AUTOSAR XML (schema 4-0-3)
standard types defined: uint8, Boolean, UInt16, UInt32, UInt8
package /AUTOSAR_Platform/DataConstrs
  range DC_Boolean: raw 0..1
  range DC_UInt16: raw 0..65535
  range DC_UInt8: raw 0..255
package /PATAC/Facility/DataTypes/Implementation
  compu method COMPU_Boolean: 0=FALSE, 1=TRUE
  unit NoUnit: factor-si-to-unit=1, offset-si-to-unit=0
package /PATAC/MSM/ComponentTypes
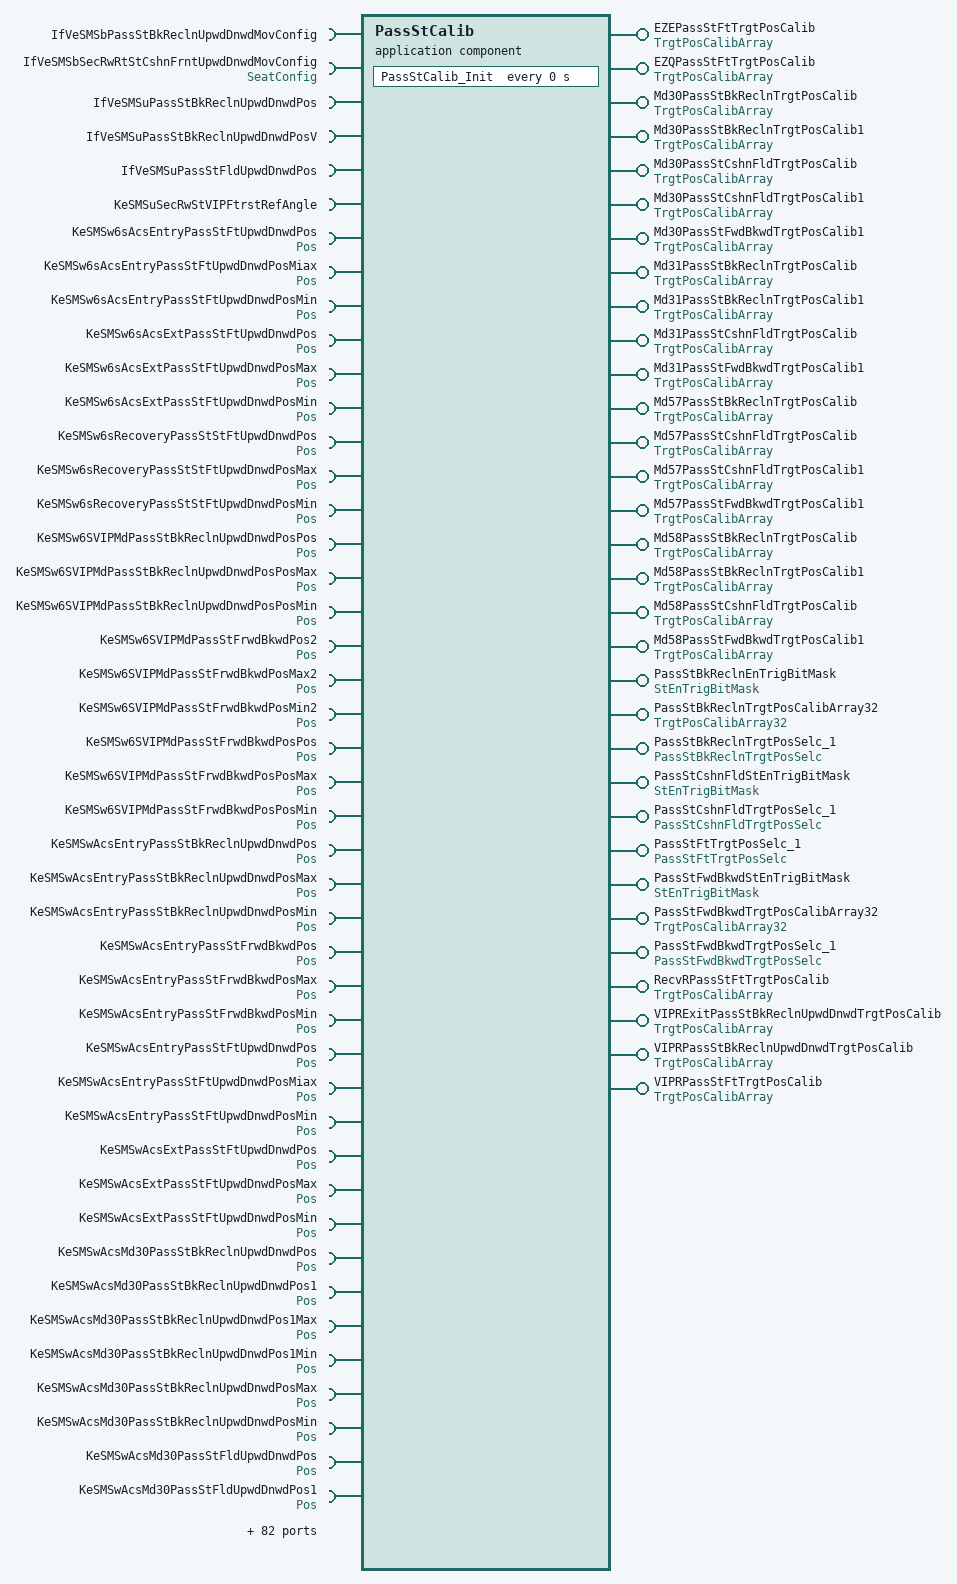
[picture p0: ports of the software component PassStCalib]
  application sw component type PassStCalib
    32 x provide port:
      EZEPassStFtTrgtPosCalib: nonqueued-sender-com-spec{data-element=TrgtPosArray, init-value=[4095, 4095, 4095]}, provided-interface=TrgtPosCalibArray
      EZQPassStFtTrgtPosCalib: nonqueued-sender-com-spec{data-element=TrgtPosArray, init-value=[4095, 4095, 4095]}, provided-interface=TrgtPosCalibArray
      Md30PassStBkReclnTrgtPosCalib: nonqueued-sender-com-spec{data-element=TrgtPosArray, init-value=[4095, 4095, 4095]}, provided-interface=TrgtPosCalibArray
      Md30PassStBkReclnTrgtPosCalib1: nonqueued-sender-com-spec{data-element=TrgtPosArray, init-value=[4095, 4095, 4095]}, provided-interface=TrgtPosCalibArray
      Md30PassStCshnFldTrgtPosCalib: nonqueued-sender-com-spec{data-element=TrgtPosArray, init-value=[4095, 4095, 4095]}, provided-interface=TrgtPosCalibArray
      Md30PassStCshnFldTrgtPosCalib1: nonqueued-sender-com-spec{data-element=TrgtPosArray, init-value=[4095, 4095, 4095]}, provided-interface=TrgtPosCalibArray
      Md30PassStFwdBkwdTrgtPosCalib1: nonqueued-sender-com-spec{data-element=TrgtPosArray, init-value=[4095, 4095, 4095]}, provided-interface=TrgtPosCalibArray
      Md31PassStBkReclnTrgtPosCalib: nonqueued-sender-com-spec{data-element=TrgtPosArray, init-value=[4095, 4095, 4095]}, provided-interface=TrgtPosCalibArray
      Md31PassStBkReclnTrgtPosCalib1: nonqueued-sender-com-spec{data-element=TrgtPosArray, init-value=[4095, 4095, 4095]}, provided-interface=TrgtPosCalibArray
      Md31PassStCshnFldTrgtPosCalib: nonqueued-sender-com-spec{data-element=TrgtPosArray, init-value=[4095, 4095, 4095]}, provided-interface=TrgtPosCalibArray
      Md31PassStFwdBkwdTrgtPosCalib1: nonqueued-sender-com-spec{data-element=TrgtPosArray, init-value=[4095, 4095, 4095]}, provided-interface=TrgtPosCalibArray
      Md57PassStBkReclnTrgtPosCalib: nonqueued-sender-com-spec{data-element=TrgtPosArray, init-value=[0, 0, 0]}, provided-interface=TrgtPosCalibArray
      Md57PassStCshnFldTrgtPosCalib: nonqueued-sender-com-spec{data-element=TrgtPosArray, init-value=[0, 0, 0]}, provided-interface=TrgtPosCalibArray
      Md57PassStCshnFldTrgtPosCalib1: nonqueued-sender-com-spec{data-element=TrgtPosArray, init-value=[0, 0, 0]}, provided-interface=TrgtPosCalibArray
      Md57PassStFwdBkwdTrgtPosCalib1: nonqueued-sender-com-spec{data-element=TrgtPosArray, init-value=[0, 0, 0]}, provided-interface=TrgtPosCalibArray
      Md58PassStBkReclnTrgtPosCalib: nonqueued-sender-com-spec{data-element=TrgtPosArray, init-value=[4095, 4095, 4095]}, provided-interface=TrgtPosCalibArray
      Md58PassStBkReclnTrgtPosCalib1: nonqueued-sender-com-spec{data-element=TrgtPosArray, init-value=[0, 0, 0]}, provided-interface=TrgtPosCalibArray
      Md58PassStCshnFldTrgtPosCalib: nonqueued-sender-com-spec{data-element=TrgtPosArray, init-value=[0, 0, 0]}, provided-interface=TrgtPosCalibArray
      Md58PassStFwdBkwdTrgtPosCalib1: nonqueued-sender-com-spec{data-element=TrgtPosArray, init-value=[0, 0, 0]}, provided-interface=TrgtPosCalibArray
      PassStBkReclnEnTrigBitMask: nonqueued-sender-com-spec{data-element=StEnTrigBitMask/Val, init-value=0}, provided-interface=StEnTrigBitMask
      PassStBkReclnTrgtPosCalibArray32: nonqueued-sender-com-spec{data-element=TrgtPosArray32, init-value=96 x 0}, provided-interface=TrgtPosCalibArray32
      PassStBkReclnTrgtPosSelc_1: server-com-spec{operation=PassStBkReclnTrgtPosSelc/Cal, queue-length=1}, provided-interface=PassStBkReclnTrgtPosSelc
      PassStCshnFldStEnTrigBitMask: nonqueued-sender-com-spec{data-element=StEnTrigBitMask/Val, init-value=0}, provided-interface=StEnTrigBitMask
      PassStCshnFldTrgtPosSelc_1: server-com-spec{operation=PassStCshnFldTrgtPosSelc/Cal, queue-length=1}, provided-interface=PassStCshnFldTrgtPosSelc
      PassStFtTrgtPosSelc_1: server-com-spec{operation=PassStFtTrgtPosSelc/Cal, queue-length=1}, provided-interface=PassStFtTrgtPosSelc
      PassStFwdBkwdStEnTrigBitMask: nonqueued-sender-com-spec{data-element=StEnTrigBitMask/Val, init-value=0}, provided-interface=StEnTrigBitMask
      PassStFwdBkwdTrgtPosCalibArray32: nonqueued-sender-com-spec{data-element=TrgtPosArray32, init-value=96 x 0}, provided-interface=TrgtPosCalibArray32
      PassStFwdBkwdTrgtPosSelc_1: server-com-spec{operation=PassStFwdBkwdTrgtPosSelc/Cal, queue-length=1}, provided-interface=PassStFwdBkwdTrgtPosSelc
      RecvRPassStFtTrgtPosCalib: nonqueued-sender-com-spec{data-element=TrgtPosArray, init-value=[4095, 4095, 4095]}, provided-interface=TrgtPosCalibArray
      VIPRExitPassStBkReclnUpwdDnwdTrgtPosCalib: nonqueued-sender-com-spec{data-element=TrgtPosArray, init-value=[4095, 4095, 4095]}, provided-interface=TrgtPosCalibArray
      VIPRPassStBkReclnUpwdDnwdTrgtPosCalib: nonqueued-sender-com-spec{data-element=TrgtPosArray, init-value=[4095, 4095, 4095]}, provided-interface=TrgtPosCalibArray
      VIPRPassStFtTrgtPosCalib: nonqueued-sender-com-spec{data-element=TrgtPosArray, init-value=[4095, 4095, 4095]}, provided-interface=TrgtPosCalibArray
    126 x require port:
      IfVeSMSbPassStBkReclnUpwdDnwdMovConfig: nonqueued-receiver-com-spec{data-element=IfVeSMSbPassStBkReclnUpwdDnwdMovConfig/Val, filter=data-filter-type=ALWAYS, init-value=0}, required-interface=IfVeSMSbPassStBkReclnUpwdDnwdMovConfig
      IfVeSMSbSecRwRtStCshnFrntUpwdDnwdMovConfig: nonqueued-receiver-com-spec{data-element=SeatConfig/Val, filter=data-filter-type=ALWAYS, init-value=0}, required-interface=SeatConfig
      IfVeSMSuPassStBkReclnUpwdDnwdPos: nonqueued-receiver-com-spec{data-element=IfVeSMSuPassStBkReclnUpwdDnwdPos/Val, filter=data-filter-type=ALWAYS, init-value=0}, required-interface=IfVeSMSuPassStBkReclnUpwdDnwdPos
      IfVeSMSuPassStBkReclnUpwdDnwdPosV: nonqueued-receiver-com-spec{data-element=IfVeSMSuPassStBkReclnUpwdDnwdPosV/Val, filter=data-filter-type=ALWAYS, init-value=0}, required-interface=IfVeSMSuPassStBkReclnUpwdDnwdPosV
      IfVeSMSuPassStFldUpwdDnwdPos: nonqueued-receiver-com-spec{data-element=IfVeSMSuPassStFldUpwdDnwdPos/Val, filter=data-filter-type=ALWAYS, init-value=0}, required-interface=IfVeSMSuPassStFldUpwdDnwdPos
      KeSMSuSecRwStVIPFtrstRefAngle: parameter-require-com-spec{init-value=110, parameter=KeSMSuSecRwStVIPFtrstRefAngle/Val}, required-interface=KeSMSuSecRwStVIPFtrstRefAngle
      KeSMSw6sAcsEntryPassStFtUpwdDnwdPos: parameter-require-com-spec{init-value=0, parameter=Pos/Val}, required-interface=Pos
      KeSMSw6sAcsEntryPassStFtUpwdDnwdPosMiax: parameter-require-com-spec{init-value=0, parameter=Pos/Val}, required-interface=Pos
      KeSMSw6sAcsEntryPassStFtUpwdDnwdPosMin: parameter-require-com-spec{init-value=0, parameter=Pos/Val}, required-interface=Pos
      KeSMSw6sAcsExtPassStFtUpwdDnwdPos: parameter-require-com-spec{init-value=0, parameter=Pos/Val}, required-interface=Pos
      KeSMSw6sAcsExtPassStFtUpwdDnwdPosMax: parameter-require-com-spec{init-value=0, parameter=Pos/Val}, required-interface=Pos
      KeSMSw6sAcsExtPassStFtUpwdDnwdPosMin: parameter-require-com-spec{init-value=0, parameter=Pos/Val}, required-interface=Pos
      KeSMSw6sRecoveryPassStStFtUpwdDnwdPos: parameter-require-com-spec{init-value=0, parameter=Pos/Val}, required-interface=Pos
      KeSMSw6sRecoveryPassStStFtUpwdDnwdPosMax: parameter-require-com-spec{init-value=0, parameter=Pos/Val}, required-interface=Pos
      KeSMSw6sRecoveryPassStStFtUpwdDnwdPosMin: parameter-require-com-spec{init-value=0, parameter=Pos/Val}, required-interface=Pos
      KeSMSw6SVIPMdPassStBkReclnUpwdDnwdPosPos: parameter-require-com-spec{init-value=0, parameter=Pos/Val}, required-interface=Pos
      KeSMSw6SVIPMdPassStBkReclnUpwdDnwdPosPosMax: parameter-require-com-spec{init-value=0, parameter=Pos/Val}, required-interface=Pos
      KeSMSw6SVIPMdPassStBkReclnUpwdDnwdPosPosMin: parameter-require-com-spec{init-value=0, parameter=Pos/Val}, required-interface=Pos
      KeSMSw6SVIPMdPassStFrwdBkwdPos2: parameter-require-com-spec{init-value=0, parameter=Pos/Val}, required-interface=Pos
      KeSMSw6SVIPMdPassStFrwdBkwdPosMax2: parameter-require-com-spec{init-value=0, parameter=Pos/Val}, required-interface=Pos
      KeSMSw6SVIPMdPassStFrwdBkwdPosMin2: parameter-require-com-spec{init-value=0, parameter=Pos/Val}, required-interface=Pos
      KeSMSw6SVIPMdPassStFrwdBkwdPosPos: parameter-require-com-spec{init-value=0, parameter=Pos/Val}, required-interface=Pos
      KeSMSw6SVIPMdPassStFrwdBkwdPosPosMax: parameter-require-com-spec{init-value=0, parameter=Pos/Val}, required-interface=Pos
      KeSMSw6SVIPMdPassStFrwdBkwdPosPosMin: parameter-require-com-spec{init-value=0, parameter=Pos/Val}, required-interface=Pos
      KeSMSwAcsEntryPassStBkReclnUpwdDnwdPos: parameter-require-com-spec{init-value=0, parameter=Pos/Val}, required-interface=Pos
      KeSMSwAcsEntryPassStBkReclnUpwdDnwdPosMax: parameter-require-com-spec{init-value=0, parameter=Pos/Val}, required-interface=Pos
      KeSMSwAcsEntryPassStBkReclnUpwdDnwdPosMin: parameter-require-com-spec{init-value=0, parameter=Pos/Val}, required-interface=Pos
      KeSMSwAcsEntryPassStFrwdBkwdPos: parameter-require-com-spec{init-value=0, parameter=Pos/Val}, required-interface=Pos
      KeSMSwAcsEntryPassStFrwdBkwdPosMax: parameter-require-com-spec{init-value=0, parameter=Pos/Val}, required-interface=Pos
      KeSMSwAcsEntryPassStFrwdBkwdPosMin: parameter-require-com-spec{init-value=0, parameter=Pos/Val}, required-interface=Pos
      KeSMSwAcsEntryPassStFtUpwdDnwdPos: parameter-require-com-spec{init-value=0, parameter=Pos/Val}, required-interface=Pos
      KeSMSwAcsEntryPassStFtUpwdDnwdPosMiax: parameter-require-com-spec{init-value=0, parameter=Pos/Val}, required-interface=Pos
      KeSMSwAcsEntryPassStFtUpwdDnwdPosMin: parameter-require-com-spec{init-value=0, parameter=Pos/Val}, required-interface=Pos
      KeSMSwAcsExtPassStFtUpwdDnwdPos: parameter-require-com-spec{init-value=0, parameter=Pos/Val}, required-interface=Pos
      KeSMSwAcsExtPassStFtUpwdDnwdPosMax: parameter-require-com-spec{init-value=0, parameter=Pos/Val}, required-interface=Pos
      KeSMSwAcsExtPassStFtUpwdDnwdPosMin: parameter-require-com-spec{init-value=0, parameter=Pos/Val}, required-interface=Pos
      KeSMSwAcsMd30PassStBkReclnUpwdDnwdPos: parameter-require-com-spec{init-value=0, parameter=Pos/Val}, required-interface=Pos
      KeSMSwAcsMd30PassStBkReclnUpwdDnwdPos1: parameter-require-com-spec{init-value=0, parameter=Pos/Val}, required-interface=Pos
      KeSMSwAcsMd30PassStBkReclnUpwdDnwdPos1Max: parameter-require-com-spec{init-value=0, parameter=Pos/Val}, required-interface=Pos
      KeSMSwAcsMd30PassStBkReclnUpwdDnwdPos1Min: parameter-require-com-spec{init-value=0, parameter=Pos/Val}, required-interface=Pos
      KeSMSwAcsMd30PassStBkReclnUpwdDnwdPosMax: parameter-require-com-spec{init-value=0, parameter=Pos/Val}, required-interface=Pos
      KeSMSwAcsMd30PassStBkReclnUpwdDnwdPosMin: parameter-require-com-spec{init-value=0, parameter=Pos/Val}, required-interface=Pos
      KeSMSwAcsMd30PassStFldUpwdDnwdPos: parameter-require-com-spec{init-value=0, parameter=Pos/Val}, required-interface=Pos
      KeSMSwAcsMd30PassStFldUpwdDnwdPos1: parameter-require-com-spec{init-value=0, parameter=Pos/Val}, required-interface=Pos
      KeSMSwAcsMd30PassStFldUpwdDnwdPos1Max: parameter-require-com-spec{init-value=0, parameter=Pos/Val}, required-interface=Pos
      KeSMSwAcsMd30PassStFldUpwdDnwdPos1Min: parameter-require-com-spec{init-value=0, parameter=Pos/Val}, required-interface=Pos
      KeSMSwAcsMd30PassStFldUpwdDnwdPosMax: parameter-require-com-spec{init-value=0, parameter=Pos/Val}, required-interface=Pos
      KeSMSwAcsMd30PassStFldUpwdDnwdPosMin: parameter-require-com-spec{init-value=0, parameter=Pos/Val}, required-interface=Pos
      KeSMSwAcsMd30PassStFrwdBkwdPos: parameter-require-com-spec{init-value=0, parameter=Pos/Val}, required-interface=Pos
      KeSMSwAcsMd30PassStFrwdBkwdPos1: parameter-require-com-spec{init-value=0, parameter=Pos/Val}, required-interface=Pos
      KeSMSwAcsMd30PassStFrwdBkwdPos1Max: parameter-require-com-spec{init-value=0, parameter=Pos/Val}, required-interface=Pos
      KeSMSwAcsMd30PassStFrwdBkwdPos1Min: parameter-require-com-spec{init-value=0, parameter=Pos/Val}, required-interface=Pos
      KeSMSwAcsMd30PassStFrwdBkwdPosMax: parameter-require-com-spec{init-value=0, parameter=Pos/Val}, required-interface=Pos
      KeSMSwAcsMd30PassStFrwdBkwdPosMin: parameter-require-com-spec{init-value=0, parameter=Pos/Val}, required-interface=Pos
      KeSMSwAcsMd31PassStBkReclnUpwdDnwdPos: parameter-require-com-spec{init-value=0, parameter=Pos/Val}, required-interface=Pos
      KeSMSwAcsMd31PassStBkReclnUpwdDnwdPos1: parameter-require-com-spec{init-value=0, parameter=Pos/Val}, required-interface=Pos
      KeSMSwAcsMd31PassStBkReclnUpwdDnwdPos1Max: parameter-require-com-spec{init-value=0, parameter=Pos/Val}, required-interface=Pos
      KeSMSwAcsMd31PassStBkReclnUpwdDnwdPos1Min: parameter-require-com-spec{init-value=0, parameter=Pos/Val}, required-interface=Pos
      KeSMSwAcsMd31PassStBkReclnUpwdDnwdPosMax: parameter-require-com-spec{init-value=0, parameter=Pos/Val}, required-interface=Pos
      KeSMSwAcsMd31PassStBkReclnUpwdDnwdPosMin: parameter-require-com-spec{init-value=0, parameter=Pos/Val}, required-interface=Pos
      KeSMSwAcsMd31PassStFldUpwdDnwdPos: parameter-require-com-spec{init-value=0, parameter=Pos/Val}, required-interface=Pos
      KeSMSwAcsMd31PassStFldUpwdDnwdPosMax: parameter-require-com-spec{init-value=0, parameter=Pos/Val}, required-interface=Pos
      KeSMSwAcsMd31PassStFldUpwdDnwdPosMin: parameter-require-com-spec{init-value=0, parameter=Pos/Val}, required-interface=Pos
      KeSMSwAcsMd31PassStFrwdBkwdPos: parameter-require-com-spec{init-value=0, parameter=Pos/Val}, required-interface=Pos
      KeSMSwAcsMd31PassStFrwdBkwdPos1: parameter-require-com-spec{init-value=0, parameter=Pos/Val}, required-interface=Pos
      KeSMSwAcsMd31PassStFrwdBkwdPos1Max: parameter-require-com-spec{init-value=0, parameter=Pos/Val}, required-interface=Pos
      KeSMSwAcsMd31PassStFrwdBkwdPos1Min: parameter-require-com-spec{init-value=0, parameter=Pos/Val}, required-interface=Pos
      KeSMSwAcsMd31PassStFrwdBkwdPosMax: parameter-require-com-spec{init-value=0, parameter=Pos/Val}, required-interface=Pos
      KeSMSwAcsMd31PassStFrwdBkwdPosMin: parameter-require-com-spec{init-value=0, parameter=Pos/Val}, required-interface=Pos
      KeSMSwAcsMd56PassStBkReclnUpwdDnwdPos: parameter-require-com-spec{init-value=0, parameter=Pos/Val}, required-interface=Pos
      KeSMSwAcsMd56PassStBkReclnUpwdDnwdPosMax: parameter-require-com-spec{init-value=0, parameter=Pos/Val}, required-interface=Pos
      KeSMSwAcsMd56PassStBkReclnUpwdDnwdPosMin: parameter-require-com-spec{init-value=0, parameter=Pos/Val}, required-interface=Pos
      KeSMSwAcsMd56PassStFrwdBkwdPos: parameter-require-com-spec{init-value=0, parameter=Pos/Val}, required-interface=Pos
      KeSMSwAcsMd56PassStFrwdBkwdPosMax: parameter-require-com-spec{init-value=0, parameter=Pos/Val}, required-interface=Pos
      KeSMSwAcsMd56PassStFrwdBkwdPosMin: parameter-require-com-spec{init-value=0, parameter=Pos/Val}, required-interface=Pos
      KeSMSwAcsMd57PassStBkReclnUpwdDnwdPosPos: parameter-require-com-spec{init-value=0, parameter=Pos/Val}, required-interface=Pos
      KeSMSwAcsMd57PassStBkReclnUpwdDnwdPosPosMax: parameter-require-com-spec{init-value=0, parameter=Pos/Val}, required-interface=Pos
      KeSMSwAcsMd57PassStBkReclnUpwdDnwdPosPosMin: parameter-require-com-spec{init-value=0, parameter=Pos/Val}, required-interface=Pos
      KeSMSwAcsMd57PassStFoldFwdBkwdPosPos: parameter-require-com-spec{init-value=0, parameter=Pos/Val}, required-interface=Pos
      KeSMSwAcsMd57PassStFoldFwdBkwdPosPos1: parameter-require-com-spec{init-value=0, parameter=Pos/Val}, required-interface=Pos
      KeSMSwAcsMd57PassStFoldFwdBkwdPosPos1Max: parameter-require-com-spec{init-value=0, parameter=Pos/Val}, required-interface=Pos
      KeSMSwAcsMd57PassStFoldFwdBkwdPosPos1Min: parameter-require-com-spec{init-value=0, parameter=Pos/Val}, required-interface=Pos
      KeSMSwAcsMd57PassStFoldFwdBkwdPosPosMax: parameter-require-com-spec{init-value=0, parameter=Pos/Val}, required-interface=Pos
      KeSMSwAcsMd57PassStFoldFwdBkwdPosPosMin: parameter-require-com-spec{init-value=0, parameter=Pos/Val}, required-interface=Pos
      KeSMSwAcsMd57PassStFrwdBkwdPosPos1: parameter-require-com-spec{init-value=0, parameter=Pos/Val}, required-interface=Pos
      KeSMSwAcsMd57PassStFrwdBkwdPosPos1Max: parameter-require-com-spec{init-value=0, parameter=Pos/Val}, required-interface=Pos
      KeSMSwAcsMd57PassStFrwdBkwdPosPos1Min: parameter-require-com-spec{init-value=0, parameter=Pos/Val}, required-interface=Pos
      KeSMSwAcsMd57PassStFrwdBkwdPosPos2: parameter-require-com-spec{init-value=0, parameter=Pos/Val}, required-interface=Pos
      KeSMSwAcsMd57PassStFrwdBkwdPosPos2Max: parameter-require-com-spec{init-value=0, parameter=Pos/Val}, required-interface=Pos
      KeSMSwAcsMd57PassStFrwdBkwdPosPos2Min: parameter-require-com-spec{init-value=0, parameter=Pos/Val}, required-interface=Pos
      KeSMSwAcsMd58PassStBkReclnUpwdDnwdPosPos1: parameter-require-com-spec{init-value=0, parameter=Pos/Val}, required-interface=Pos
      KeSMSwAcsMd58PassStBkReclnUpwdDnwdPosPos1Max: parameter-require-com-spec{init-value=0, parameter=Pos/Val}, required-interface=Pos
      KeSMSwAcsMd58PassStBkReclnUpwdDnwdPosPos1Min: parameter-require-com-spec{init-value=0, parameter=Pos/Val}, required-interface=Pos
      KeSMSwAcsMd58PassStFrwdBkwdPosPos1: parameter-require-com-spec{init-value=0, parameter=Pos/Val}, required-interface=Pos
      KeSMSwAcsMd58PassStFrwdBkwdPosPos1Max: parameter-require-com-spec{init-value=0, parameter=Pos/Val}, required-interface=Pos
      KeSMSwAcsMd58PassStFrwdBkwdPosPos1Min: parameter-require-com-spec{init-value=0, parameter=Pos/Val}, required-interface=Pos
      KeSMSwPassStBkReclnEnTrig557BitMask: parameter-require-com-spec{init-value=6153, parameter=StEnTrigBitMask/Val}, required-interface=StEnTrigBitMask
      KeSMSwPassStCshnFldEnTrig557BitMask: parameter-require-com-spec{init-value=6153, parameter=StEnTrigBitMask/Val}, required-interface=StEnTrigBitMask
      KeSMSwPassStFwdBkwdEnTrig557BitMask: parameter-require-com-spec{init-value=6153, parameter=StEnTrigBitMask/Val}, required-interface=StEnTrigBitMask
      KeSMSwRecoveryPassStStFtUpwdDnwdPos: parameter-require-com-spec{init-value=0, parameter=Pos/Val}, required-interface=Pos
      KeSMSwRecoveryPassStStFtUpwdDnwdPosMax: parameter-require-com-spec{init-value=0, parameter=Pos/Val}, required-interface=Pos
      KeSMSwRecoveryPassStStFtUpwdDnwdPosMin: parameter-require-com-spec{init-value=0, parameter=Pos/Val}, required-interface=Pos
      KeSMSwRevRMDPassStBkReclnUpwdDnwdPos: parameter-require-com-spec{init-value=0, parameter=Pos/Val}, required-interface=Pos
      KeSMSwRevRMDPassStBkReclnUpwdDnwdPosMax: parameter-require-com-spec{init-value=0, parameter=Pos/Val}, required-interface=Pos
      KeSMSwRevRMDPassStBkReclnUpwdDnwdPosMin: parameter-require-com-spec{init-value=0, parameter=Pos/Val}, required-interface=Pos
      KeSMSwRevRMDPassStFrwdBkwdPos: parameter-require-com-spec{init-value=0, parameter=Pos/Val}, required-interface=Pos
      KeSMSwRevRMDPassStFrwdBkwdPosMax: parameter-require-com-spec{init-value=0, parameter=Pos/Val}, required-interface=Pos
      KeSMSwRevRMDPassStFrwdBkwdPosMin: parameter-require-com-spec{init-value=0, parameter=Pos/Val}, required-interface=Pos
      KeSMSwVIPMDPassStBkReclnUpwdDnwdPosPos: parameter-require-com-spec{init-value=0, parameter=Pos/Val}, required-interface=Pos
      KeSMSwVIPMDPassStBkReclnUpwdDnwdPosPosMax: parameter-require-com-spec{init-value=0, parameter=Pos/Val}, required-interface=Pos
      KeSMSwVIPMDPassStBkReclnUpwdDnwdPosPosMin: parameter-require-com-spec{init-value=0, parameter=Pos/Val}, required-interface=Pos
      KeSMSwVIPMDPassStFrwdBkwdPos2: parameter-require-com-spec{init-value=0, parameter=Pos/Val}, required-interface=Pos
      KeSMSwVIPMDPassStFrwdBkwdPosMax2: parameter-require-com-spec{init-value=0, parameter=Pos/Val}, required-interface=Pos
      KeSMSwVIPMDPassStFrwdBkwdPosMin2: parameter-require-com-spec{init-value=0, parameter=Pos/Val}, required-interface=Pos
      KeSMSwVIPMDPassStFrwdBkwdPosPos: parameter-require-com-spec{init-value=0, parameter=Pos/Val}, required-interface=Pos
      KeSMSwVIPMDPassStFrwdBkwdPosPosMax: parameter-require-com-spec{init-value=0, parameter=Pos/Val}, required-interface=Pos
      KeSMSwVIPMDPassStFrwdBkwdPosPosMin: parameter-require-com-spec{init-value=0, parameter=Pos/Val}, required-interface=Pos
      Md30BkStgDone: nonqueued-receiver-com-spec{data-element=StgDone/Val, filter=data-filter-type=ALWAYS, init-value=0}, required-interface=StgDone
      Md31BkStgDone: nonqueued-receiver-com-spec{data-element=StgDone/Val, filter=data-filter-type=ALWAYS, init-value=0}, required-interface=StgDone
      Md58TrgtPos: required-com-specs=[Md58TrgtPos/Get, Md58TrgtPos/Set], required-interface=Md58TrgtPos
      Md61PassStBkReclnTrgtPosCalib: nonqueued-receiver-com-spec{data-element=TrgtPosArray, filter=data-filter-type=ALWAYS, init-value=[4095, 4095, 4095]}, required-interface=TrgtPosCalibArray
      Md61PassStFwdBkwdTrgtPosCalib: nonqueued-receiver-com-spec{data-element=TrgtPosArray, filter=data-filter-type=ALWAYS, init-value=[4095, 4095, 4095]}, required-interface=TrgtPosCalibArray
      Md62PassStBkReclnTrgtPosCalib: nonqueued-receiver-com-spec{data-element=TrgtPosArray, filter=data-filter-type=ALWAYS, init-value=[4095, 4095, 4095]}, required-interface=TrgtPosCalibArray
      Md62PassStFwdBkwdTrgtPosCalib: nonqueued-receiver-com-spec{data-element=TrgtPosArray, filter=data-filter-type=ALWAYS, init-value=[4095, 4095, 4095]}, required-interface=TrgtPosCalibArray
      StNumFlg: required-interface=StNumFlg
        required-com-specs:
          data-element=Is4s, filter=data-filter-type=ALWAYS, init-value=0
          data-element=Is6s, filter=data-filter-type=ALWAYS, init-value=0
          data-element=Is6s7s, filter=data-filter-type=ALWAYS, init-value=0
          data-element=Is7s, filter=data-filter-type=ALWAYS, init-value=0
      VIPRExit557TrgtPos: required-com-specs=[VIPRExit557TrgtPos/Get, VIPRExit557TrgtPos/Set], required-interface=VIPRExit557TrgtPos
    behavior PassStCalib_InternalBehavior
      operation invoked event OIT_PassStBkReclnTrgtPosSelc_1_Cal_PassStBkReclnTrgtPosSelc_1_Cal: start-on-event=PassStBkReclnTrgtPosSelc_1_Cal, operation=PassStBkReclnTrgtPosSelc_1.Cal
      timing event PassStCalib_InitEvent: start-on-event=PassStCalib_Init, period=0
      operation invoked event OIT_PassStCshnFldTrgtPosSelc_1_Cal_PassStCshnFldTrgtPosSelc_1_Cal: start-on-event=PassStCshnFldTrgtPosSelc_1_Cal, operation=PassStCshnFldTrgtPosSelc_1.Cal
      operation invoked event OIT_PassStFtTrgtPosSelc_1_Cal_PassStFtTrgtPosSelc_1_Cal: start-on-event=PassStFtTrgtPosSelc_1_Cal, operation=PassStFtTrgtPosSelc_1.Cal
      operation invoked event OIT_PassStFwdBkwdTrgtPosSelc_1_Cal_PassStFwdBkwdTrgtPosSelc_1_Cal: start-on-event=PassStFwdBkwdTrgtPosSelc_1_Cal, operation=PassStFwdBkwdTrgtPosSelc_1.Cal
      5 x runnable:
        PassStBkReclnTrgtPosSelc_1_Cal
          data-receive-point-by-arguments:
            8 x access:
              REC_IfVeSMSbSecRwRtStCshnFrntUpwdDnwdMovConfig_Val: accessed-variable=IfVeSMSbSecRwRtStCshnFrntUpwdDnwdMovConfig.Val
              REC_IfVeSMSuPassStFldUpwdDnwdPos_Val: accessed-variable=IfVeSMSuPassStFldUpwdDnwdPos.Val
              REC_Md61PassStBkReclnTrgtPosCalib_TrgtPosArray: accessed-variable=Md61PassStBkReclnTrgtPosCalib.TrgtPosArray
              REC_Md62PassStBkReclnTrgtPosCalib_TrgtPosArray: accessed-variable=Md62PassStBkReclnTrgtPosCalib.TrgtPosArray
              REC_StNumFlg_Is4s: accessed-variable=StNumFlg.Is4s
              REC_StNumFlg_Is6s: accessed-variable=StNumFlg.Is6s
              REC_StNumFlg_Is6s7s: accessed-variable=StNumFlg.Is6s7s
              REC_StNumFlg_Is7s: accessed-variable=StNumFlg.Is7s
          data-send-points:
            11 x access:
              SEND_Md30PassStBkReclnTrgtPosCalib_TrgtPosArray: accessed-variable=Md30PassStBkReclnTrgtPosCalib.TrgtPosArray
              SEND_Md30PassStBkReclnTrgtPosCalib1_TrgtPosArray: accessed-variable=Md30PassStBkReclnTrgtPosCalib1.TrgtPosArray
              SEND_Md31PassStBkReclnTrgtPosCalib_TrgtPosArray: accessed-variable=Md31PassStBkReclnTrgtPosCalib.TrgtPosArray
              SEND_Md31PassStBkReclnTrgtPosCalib1_TrgtPosArray: accessed-variable=Md31PassStBkReclnTrgtPosCalib1.TrgtPosArray
              SEND_Md57PassStBkReclnTrgtPosCalib_TrgtPosArray: accessed-variable=Md57PassStBkReclnTrgtPosCalib.TrgtPosArray
              SEND_Md58PassStBkReclnTrgtPosCalib_TrgtPosArray: accessed-variable=Md58PassStBkReclnTrgtPosCalib.TrgtPosArray
              SEND_Md58PassStBkReclnTrgtPosCalib1_TrgtPosArray: accessed-variable=Md58PassStBkReclnTrgtPosCalib1.TrgtPosArray
              SEND_PassStBkReclnEnTrigBitMask_Val: accessed-variable=PassStBkReclnEnTrigBitMask.Val
              SEND_PassStBkReclnTrgtPosCalibArray32_TrgtPosArray32: accessed-variable=PassStBkReclnTrgtPosCalibArray32.TrgtPosArray32
              SEND_VIPRExitPassStBkReclnUpwdDnwdTrgtPosCalib_TrgtPosArray: accessed-variable=VIPRExitPassStBkReclnUpwdDnwdTrgtPosCalib.TrgtPosArray
              SEND_VIPRPassStBkReclnUpwdDnwdTrgtPosCalib_TrgtPosArray: accessed-variable=VIPRPassStBkReclnUpwdDnwdTrgtPosCalib.TrgtPosArray
          112 x parameter access:
            PA_KeSMSuSecRwStVIPFtrstRefAngle_Val: accessed-parameter=KeSMSuSecRwStVIPFtrstRefAngle.Val
            PA_KeSMSw6sAcsEntryPassStFtUpwdDnwdPos_Val: accessed-parameter=KeSMSw6sAcsEntryPassStFtUpwdDnwdPos.Val
            PA_KeSMSw6sAcsEntryPassStFtUpwdDnwdPosMiax_Val: accessed-parameter=KeSMSw6sAcsEntryPassStFtUpwdDnwdPosMiax.Val
            PA_KeSMSw6sAcsEntryPassStFtUpwdDnwdPosMin_Val: accessed-parameter=KeSMSw6sAcsEntryPassStFtUpwdDnwdPosMin.Val
            PA_KeSMSw6sAcsExtPassStFtUpwdDnwdPos_Val: accessed-parameter=KeSMSw6sAcsExtPassStFtUpwdDnwdPos.Val
            PA_KeSMSw6sAcsExtPassStFtUpwdDnwdPosMax_Val: accessed-parameter=KeSMSw6sAcsExtPassStFtUpwdDnwdPosMax.Val
            PA_KeSMSw6sAcsExtPassStFtUpwdDnwdPosMin_Val: accessed-parameter=KeSMSw6sAcsExtPassStFtUpwdDnwdPosMin.Val
            PA_KeSMSw6sRecoveryPassStStFtUpwdDnwdPos_Val: accessed-parameter=KeSMSw6sRecoveryPassStStFtUpwdDnwdPos.Val
            PA_KeSMSw6sRecoveryPassStStFtUpwdDnwdPosMax_Val: accessed-parameter=KeSMSw6sRecoveryPassStStFtUpwdDnwdPosMax.Val
            PA_KeSMSw6sRecoveryPassStStFtUpwdDnwdPosMin_Val: accessed-parameter=KeSMSw6sRecoveryPassStStFtUpwdDnwdPosMin.Val
            PA_KeSMSw6SVIPMdPassStBkReclnUpwdDnwdPosPos_Val: accessed-parameter=KeSMSw6SVIPMdPassStBkReclnUpwdDnwdPosPos.Val
            PA_KeSMSw6SVIPMdPassStBkReclnUpwdDnwdPosPosMax_Val: accessed-parameter=KeSMSw6SVIPMdPassStBkReclnUpwdDnwdPosPosMax.Val
            PA_KeSMSw6SVIPMdPassStBkReclnUpwdDnwdPosPosMin_Val: accessed-parameter=KeSMSw6SVIPMdPassStBkReclnUpwdDnwdPosPosMin.Val
            PA_KeSMSw6SVIPMdPassStFrwdBkwdPos2_Val: accessed-parameter=KeSMSw6SVIPMdPassStFrwdBkwdPos2.Val
            PA_KeSMSw6SVIPMdPassStFrwdBkwdPosMax2_Val: accessed-parameter=KeSMSw6SVIPMdPassStFrwdBkwdPosMax2.Val
            PA_KeSMSw6SVIPMdPassStFrwdBkwdPosMin2_Val: accessed-parameter=KeSMSw6SVIPMdPassStFrwdBkwdPosMin2.Val
            PA_KeSMSw6SVIPMdPassStFrwdBkwdPosPos_Val: accessed-parameter=KeSMSw6SVIPMdPassStFrwdBkwdPosPos.Val
            PA_KeSMSw6SVIPMdPassStFrwdBkwdPosPosMax_Val: accessed-parameter=KeSMSw6SVIPMdPassStFrwdBkwdPosPosMax.Val
            PA_KeSMSw6SVIPMdPassStFrwdBkwdPosPosMin_Val: accessed-parameter=KeSMSw6SVIPMdPassStFrwdBkwdPosPosMin.Val
            PA_KeSMSwAcsEntryPassStBkReclnUpwdDnwdPos_Val: accessed-parameter=KeSMSwAcsEntryPassStBkReclnUpwdDnwdPos.Val
            PA_KeSMSwAcsEntryPassStBkReclnUpwdDnwdPosMax_Val: accessed-parameter=KeSMSwAcsEntryPassStBkReclnUpwdDnwdPosMax.Val
            PA_KeSMSwAcsEntryPassStBkReclnUpwdDnwdPosMin_Val: accessed-parameter=KeSMSwAcsEntryPassStBkReclnUpwdDnwdPosMin.Val
            PA_KeSMSwAcsEntryPassStFrwdBkwdPos_Val: accessed-parameter=KeSMSwAcsEntryPassStFrwdBkwdPos.Val
            PA_KeSMSwAcsEntryPassStFrwdBkwdPosMax_Val: accessed-parameter=KeSMSwAcsEntryPassStFrwdBkwdPosMax.Val
            PA_KeSMSwAcsEntryPassStFrwdBkwdPosMin_Val: accessed-parameter=KeSMSwAcsEntryPassStFrwdBkwdPosMin.Val
            PA_KeSMSwAcsEntryPassStFtUpwdDnwdPos_Val: accessed-parameter=KeSMSwAcsEntryPassStFtUpwdDnwdPos.Val
            PA_KeSMSwAcsEntryPassStFtUpwdDnwdPosMiax_Val: accessed-parameter=KeSMSwAcsEntryPassStFtUpwdDnwdPosMiax.Val
            PA_KeSMSwAcsEntryPassStFtUpwdDnwdPosMin_Val: accessed-parameter=KeSMSwAcsEntryPassStFtUpwdDnwdPosMin.Val
            PA_KeSMSwAcsExtPassStFtUpwdDnwdPos_Val: accessed-parameter=KeSMSwAcsExtPassStFtUpwdDnwdPos.Val
            PA_KeSMSwAcsExtPassStFtUpwdDnwdPosMax_Val: accessed-parameter=KeSMSwAcsExtPassStFtUpwdDnwdPosMax.Val
            PA_KeSMSwAcsExtPassStFtUpwdDnwdPosMin_Val: accessed-parameter=KeSMSwAcsExtPassStFtUpwdDnwdPosMin.Val
            PA_KeSMSwAcsMd30PassStBkReclnUpwdDnwdPos_Val: accessed-parameter=KeSMSwAcsMd30PassStBkReclnUpwdDnwdPos.Val
            PA_KeSMSwAcsMd30PassStBkReclnUpwdDnwdPos1_Val: accessed-parameter=KeSMSwAcsMd30PassStBkReclnUpwdDnwdPos1.Val
            PA_KeSMSwAcsMd30PassStBkReclnUpwdDnwdPos1Max_Val: accessed-parameter=KeSMSwAcsMd30PassStBkReclnUpwdDnwdPos1Max.Val
            PA_KeSMSwAcsMd30PassStBkReclnUpwdDnwdPos1Min_Val: accessed-parameter=KeSMSwAcsMd30PassStBkReclnUpwdDnwdPos1Min.Val
            PA_KeSMSwAcsMd30PassStBkReclnUpwdDnwdPosMax_Val: accessed-parameter=KeSMSwAcsMd30PassStBkReclnUpwdDnwdPosMax.Val
            PA_KeSMSwAcsMd30PassStBkReclnUpwdDnwdPosMin_Val: accessed-parameter=KeSMSwAcsMd30PassStBkReclnUpwdDnwdPosMin.Val
            PA_KeSMSwAcsMd30PassStFldUpwdDnwdPos_Val: accessed-parameter=KeSMSwAcsMd30PassStFldUpwdDnwdPos.Val
            PA_KeSMSwAcsMd30PassStFldUpwdDnwdPos1_Val: accessed-parameter=KeSMSwAcsMd30PassStFldUpwdDnwdPos1.Val
            PA_KeSMSwAcsMd30PassStFldUpwdDnwdPos1Max_Val: accessed-parameter=KeSMSwAcsMd30PassStFldUpwdDnwdPos1Max.Val
            PA_KeSMSwAcsMd30PassStFldUpwdDnwdPos1Min_Val: accessed-parameter=KeSMSwAcsMd30PassStFldUpwdDnwdPos1Min.Val
            PA_KeSMSwAcsMd30PassStFldUpwdDnwdPosMax_Val: accessed-parameter=KeSMSwAcsMd30PassStFldUpwdDnwdPosMax.Val
            PA_KeSMSwAcsMd30PassStFldUpwdDnwdPosMin_Val: accessed-parameter=KeSMSwAcsMd30PassStFldUpwdDnwdPosMin.Val
            PA_KeSMSwAcsMd30PassStFrwdBkwdPos_Val: accessed-parameter=KeSMSwAcsMd30PassStFrwdBkwdPos.Val
            PA_KeSMSwAcsMd30PassStFrwdBkwdPos1_Val: accessed-parameter=KeSMSwAcsMd30PassStFrwdBkwdPos1.Val
            PA_KeSMSwAcsMd30PassStFrwdBkwdPos1Max_Val: accessed-parameter=KeSMSwAcsMd30PassStFrwdBkwdPos1Max.Val
            PA_KeSMSwAcsMd30PassStFrwdBkwdPos1Min_Val: accessed-parameter=KeSMSwAcsMd30PassStFrwdBkwdPos1Min.Val
            PA_KeSMSwAcsMd30PassStFrwdBkwdPosMax_Val: accessed-parameter=KeSMSwAcsMd30PassStFrwdBkwdPosMax.Val
            PA_KeSMSwAcsMd30PassStFrwdBkwdPosMin_Val: accessed-parameter=KeSMSwAcsMd30PassStFrwdBkwdPosMin.Val
            PA_KeSMSwAcsMd31PassStBkReclnUpwdDnwdPos_Val: accessed-parameter=KeSMSwAcsMd31PassStBkReclnUpwdDnwdPos.Val
            PA_KeSMSwAcsMd31PassStBkReclnUpwdDnwdPos1_Val: accessed-parameter=KeSMSwAcsMd31PassStBkReclnUpwdDnwdPos1.Val
            PA_KeSMSwAcsMd31PassStBkReclnUpwdDnwdPos1Max_Val: accessed-parameter=KeSMSwAcsMd31PassStBkReclnUpwdDnwdPos1Max.Val
            PA_KeSMSwAcsMd31PassStBkReclnUpwdDnwdPos1Min_Val: accessed-parameter=KeSMSwAcsMd31PassStBkReclnUpwdDnwdPos1Min.Val
            PA_KeSMSwAcsMd31PassStBkReclnUpwdDnwdPosMax_Val: accessed-parameter=KeSMSwAcsMd31PassStBkReclnUpwdDnwdPosMax.Val
            PA_KeSMSwAcsMd31PassStBkReclnUpwdDnwdPosMin_Val: accessed-parameter=KeSMSwAcsMd31PassStBkReclnUpwdDnwdPosMin.Val
            PA_KeSMSwAcsMd31PassStFldUpwdDnwdPos_Val: accessed-parameter=KeSMSwAcsMd31PassStFldUpwdDnwdPos.Val
            PA_KeSMSwAcsMd31PassStFldUpwdDnwdPosMax_Val: accessed-parameter=KeSMSwAcsMd31PassStFldUpwdDnwdPosMax.Val
            PA_KeSMSwAcsMd31PassStFldUpwdDnwdPosMin_Val: accessed-parameter=KeSMSwAcsMd31PassStFldUpwdDnwdPosMin.Val
            PA_KeSMSwAcsMd31PassStFrwdBkwdPos_Val: accessed-parameter=KeSMSwAcsMd31PassStFrwdBkwdPos.Val
            PA_KeSMSwAcsMd31PassStFrwdBkwdPos1_Val: accessed-parameter=KeSMSwAcsMd31PassStFrwdBkwdPos1.Val
            PA_KeSMSwAcsMd31PassStFrwdBkwdPos1Max_Val: accessed-parameter=KeSMSwAcsMd31PassStFrwdBkwdPos1Max.Val
            PA_KeSMSwAcsMd31PassStFrwdBkwdPos1Min_Val: accessed-parameter=KeSMSwAcsMd31PassStFrwdBkwdPos1Min.Val
            PA_KeSMSwAcsMd31PassStFrwdBkwdPosMax_Val: accessed-parameter=KeSMSwAcsMd31PassStFrwdBkwdPosMax.Val
            PA_KeSMSwAcsMd31PassStFrwdBkwdPosMin_Val: accessed-parameter=KeSMSwAcsMd31PassStFrwdBkwdPosMin.Val
            PA_KeSMSwAcsMd56PassStBkReclnUpwdDnwdPos_Val: accessed-parameter=KeSMSwAcsMd56PassStBkReclnUpwdDnwdPos.Val
            PA_KeSMSwAcsMd56PassStBkReclnUpwdDnwdPosMax_Val: accessed-parameter=KeSMSwAcsMd56PassStBkReclnUpwdDnwdPosMax.Val
            PA_KeSMSwAcsMd56PassStBkReclnUpwdDnwdPosMin_Val: accessed-parameter=KeSMSwAcsMd56PassStBkReclnUpwdDnwdPosMin.Val
            PA_KeSMSwAcsMd56PassStFrwdBkwdPos_Val: accessed-parameter=KeSMSwAcsMd56PassStFrwdBkwdPos.Val
            PA_KeSMSwAcsMd56PassStFrwdBkwdPosMax_Val: accessed-parameter=KeSMSwAcsMd56PassStFrwdBkwdPosMax.Val
            PA_KeSMSwAcsMd56PassStFrwdBkwdPosMin_Val: accessed-parameter=KeSMSwAcsMd56PassStFrwdBkwdPosMin.Val
            PA_KeSMSwAcsMd57PassStBkReclnUpwdDnwdPosPos_Val: accessed-parameter=KeSMSwAcsMd57PassStBkReclnUpwdDnwdPosPos.Val
            PA_KeSMSwAcsMd57PassStBkReclnUpwdDnwdPosPosMax_Val: accessed-parameter=KeSMSwAcsMd57PassStBkReclnUpwdDnwdPosPosMax.Val
            PA_KeSMSwAcsMd57PassStBkReclnUpwdDnwdPosPosMin_Val: accessed-parameter=KeSMSwAcsMd57PassStBkReclnUpwdDnwdPosPosMin.Val
            PA_KeSMSwAcsMd57PassStFoldFwdBkwdPosPos_Val: accessed-parameter=KeSMSwAcsMd57PassStFoldFwdBkwdPosPos.Val
            PA_KeSMSwAcsMd57PassStFoldFwdBkwdPosPos1_Val: accessed-parameter=KeSMSwAcsMd57PassStFoldFwdBkwdPosPos1.Val
            PA_KeSMSwAcsMd57PassStFoldFwdBkwdPosPos1Max_Val: accessed-parameter=KeSMSwAcsMd57PassStFoldFwdBkwdPosPos1Max.Val
            PA_KeSMSwAcsMd57PassStFoldFwdBkwdPosPos1Min_Val: accessed-parameter=KeSMSwAcsMd57PassStFoldFwdBkwdPosPos1Min.Val
            PA_KeSMSwAcsMd57PassStFoldFwdBkwdPosPosMax_Val: accessed-parameter=KeSMSwAcsMd57PassStFoldFwdBkwdPosPosMax.Val
            PA_KeSMSwAcsMd57PassStFoldFwdBkwdPosPosMin_Val: accessed-parameter=KeSMSwAcsMd57PassStFoldFwdBkwdPosPosMin.Val
            PA_KeSMSwAcsMd57PassStFrwdBkwdPosPos1_Val: accessed-parameter=KeSMSwAcsMd57PassStFrwdBkwdPosPos1.Val
            PA_KeSMSwAcsMd57PassStFrwdBkwdPosPos1Max_Val: accessed-parameter=KeSMSwAcsMd57PassStFrwdBkwdPosPos1Max.Val
            PA_KeSMSwAcsMd57PassStFrwdBkwdPosPos1Min_Val: accessed-parameter=KeSMSwAcsMd57PassStFrwdBkwdPosPos1Min.Val
            PA_KeSMSwAcsMd57PassStFrwdBkwdPosPos2_Val: accessed-parameter=KeSMSwAcsMd57PassStFrwdBkwdPosPos2.Val
            PA_KeSMSwAcsMd57PassStFrwdBkwdPosPos2Max_Val: accessed-parameter=KeSMSwAcsMd57PassStFrwdBkwdPosPos2Max.Val
            PA_KeSMSwAcsMd57PassStFrwdBkwdPosPos2Min_Val: accessed-parameter=KeSMSwAcsMd57PassStFrwdBkwdPosPos2Min.Val
            PA_KeSMSwAcsMd58PassStBkReclnUpwdDnwdPosPos1_Val: accessed-parameter=KeSMSwAcsMd58PassStBkReclnUpwdDnwdPosPos1.Val
            PA_KeSMSwAcsMd58PassStBkReclnUpwdDnwdPosPos1Max_Val: accessed-parameter=KeSMSwAcsMd58PassStBkReclnUpwdDnwdPosPos1Max.Val
            PA_KeSMSwAcsMd58PassStBkReclnUpwdDnwdPosPos1Min_Val: accessed-parameter=KeSMSwAcsMd58PassStBkReclnUpwdDnwdPosPos1Min.Val
            PA_KeSMSwAcsMd58PassStFrwdBkwdPosPos1_Val: accessed-parameter=KeSMSwAcsMd58PassStFrwdBkwdPosPos1.Val
            PA_KeSMSwAcsMd58PassStFrwdBkwdPosPos1Max_Val: accessed-parameter=KeSMSwAcsMd58PassStFrwdBkwdPosPos1Max.Val
            PA_KeSMSwAcsMd58PassStFrwdBkwdPosPos1Min_Val: accessed-parameter=KeSMSwAcsMd58PassStFrwdBkwdPosPos1Min.Val
            PA_KeSMSwPassStBkReclnEnTrig557BitMask_Val: accessed-parameter=KeSMSwPassStBkReclnEnTrig557BitMask.Val
            PA_KeSMSwPassStCshnFldEnTrig557BitMask_Val: accessed-parameter=KeSMSwPassStCshnFldEnTrig557BitMask.Val
            PA_KeSMSwPassStFwdBkwdEnTrig557BitMask_Val: accessed-parameter=KeSMSwPassStFwdBkwdEnTrig557BitMask.Val
            PA_KeSMSwRecoveryPassStStFtUpwdDnwdPos_Val: accessed-parameter=KeSMSwRecoveryPassStStFtUpwdDnwdPos.Val
            PA_KeSMSwRecoveryPassStStFtUpwdDnwdPosMax_Val: accessed-parameter=KeSMSwRecoveryPassStStFtUpwdDnwdPosMax.Val
            PA_KeSMSwRecoveryPassStStFtUpwdDnwdPosMin_Val: accessed-parameter=KeSMSwRecoveryPassStStFtUpwdDnwdPosMin.Val
            PA_KeSMSwRevRMDPassStBkReclnUpwdDnwdPos_Val: accessed-parameter=KeSMSwRevRMDPassStBkReclnUpwdDnwdPos.Val
            PA_KeSMSwRevRMDPassStBkReclnUpwdDnwdPosMax_Val: accessed-parameter=KeSMSwRevRMDPassStBkReclnUpwdDnwdPosMax.Val
            PA_KeSMSwRevRMDPassStBkReclnUpwdDnwdPosMin_Val: accessed-parameter=KeSMSwRevRMDPassStBkReclnUpwdDnwdPosMin.Val
            PA_KeSMSwRevRMDPassStFrwdBkwdPos_Val: accessed-parameter=KeSMSwRevRMDPassStFrwdBkwdPos.Val
            PA_KeSMSwRevRMDPassStFrwdBkwdPosMax_Val: accessed-parameter=KeSMSwRevRMDPassStFrwdBkwdPosMax.Val
            PA_KeSMSwRevRMDPassStFrwdBkwdPosMin_Val: accessed-parameter=KeSMSwRevRMDPassStFrwdBkwdPosMin.Val
            PA_KeSMSwVIPMDPassStBkReclnUpwdDnwdPosPos_Val: accessed-parameter=KeSMSwVIPMDPassStBkReclnUpwdDnwdPosPos.Val
            PA_KeSMSwVIPMDPassStBkReclnUpwdDnwdPosPosMax_Val: accessed-parameter=KeSMSwVIPMDPassStBkReclnUpwdDnwdPosPosMax.Val
            PA_KeSMSwVIPMDPassStBkReclnUpwdDnwdPosPosMin_Val: accessed-parameter=KeSMSwVIPMDPassStBkReclnUpwdDnwdPosPosMin.Val
            PA_KeSMSwVIPMDPassStFrwdBkwdPos2_Val: accessed-parameter=KeSMSwVIPMDPassStFrwdBkwdPos2.Val
            PA_KeSMSwVIPMDPassStFrwdBkwdPosMax2_Val: accessed-parameter=KeSMSwVIPMDPassStFrwdBkwdPosMax2.Val
            PA_KeSMSwVIPMDPassStFrwdBkwdPosMin2_Val: accessed-parameter=KeSMSwVIPMDPassStFrwdBkwdPosMin2.Val
            PA_KeSMSwVIPMDPassStFrwdBkwdPosPos_Val: accessed-parameter=KeSMSwVIPMDPassStFrwdBkwdPosPos.Val
            PA_KeSMSwVIPMDPassStFrwdBkwdPosPosMax_Val: accessed-parameter=KeSMSwVIPMDPassStFrwdBkwdPosPosMax.Val
            PA_KeSMSwVIPMDPassStFrwdBkwdPosPosMin_Val: accessed-parameter=KeSMSwVIPMDPassStFrwdBkwdPosPosMin.Val
          sync call SC_Md58TrgtPos_Get: operation=Md58TrgtPos.Get, timeout=0
          sync call SC_VIPRExit557TrgtPos_Get: operation=VIPRExit557TrgtPos.Get, timeout=0
        PassStCalib_Init
          112 x parameter access:
            PA_KeSMSuSecRwStVIPFtrstRefAngle_Val: accessed-parameter=KeSMSuSecRwStVIPFtrstRefAngle.Val
            PA_KeSMSw6sAcsEntryPassStFtUpwdDnwdPos_Val: accessed-parameter=KeSMSw6sAcsEntryPassStFtUpwdDnwdPos.Val
            PA_KeSMSw6sAcsEntryPassStFtUpwdDnwdPosMiax_Val: accessed-parameter=KeSMSw6sAcsEntryPassStFtUpwdDnwdPosMiax.Val
            PA_KeSMSw6sAcsEntryPassStFtUpwdDnwdPosMin_Val: accessed-parameter=KeSMSw6sAcsEntryPassStFtUpwdDnwdPosMin.Val
            PA_KeSMSw6sAcsExtPassStFtUpwdDnwdPos_Val: accessed-parameter=KeSMSw6sAcsExtPassStFtUpwdDnwdPos.Val
            PA_KeSMSw6sAcsExtPassStFtUpwdDnwdPosMax_Val: accessed-parameter=KeSMSw6sAcsExtPassStFtUpwdDnwdPosMax.Val
            PA_KeSMSw6sAcsExtPassStFtUpwdDnwdPosMin_Val: accessed-parameter=KeSMSw6sAcsExtPassStFtUpwdDnwdPosMin.Val
            PA_KeSMSw6sRecoveryPassStStFtUpwdDnwdPos_Val: accessed-parameter=KeSMSw6sRecoveryPassStStFtUpwdDnwdPos.Val
            PA_KeSMSw6sRecoveryPassStStFtUpwdDnwdPosMax_Val: accessed-parameter=KeSMSw6sRecoveryPassStStFtUpwdDnwdPosMax.Val
            PA_KeSMSw6sRecoveryPassStStFtUpwdDnwdPosMin_Val: accessed-parameter=KeSMSw6sRecoveryPassStStFtUpwdDnwdPosMin.Val
            PA_KeSMSw6SVIPMdPassStBkReclnUpwdDnwdPosPos_Val: accessed-parameter=KeSMSw6SVIPMdPassStBkReclnUpwdDnwdPosPos.Val
            PA_KeSMSw6SVIPMdPassStBkReclnUpwdDnwdPosPosMax_Val: accessed-parameter=KeSMSw6SVIPMdPassStBkReclnUpwdDnwdPosPosMax.Val
            PA_KeSMSw6SVIPMdPassStBkReclnUpwdDnwdPosPosMin_Val: accessed-parameter=KeSMSw6SVIPMdPassStBkReclnUpwdDnwdPosPosMin.Val
            PA_KeSMSw6SVIPMdPassStFrwdBkwdPos2_Val: accessed-parameter=KeSMSw6SVIPMdPassStFrwdBkwdPos2.Val
            PA_KeSMSw6SVIPMdPassStFrwdBkwdPosMax2_Val: accessed-parameter=KeSMSw6SVIPMdPassStFrwdBkwdPosMax2.Val
            PA_KeSMSw6SVIPMdPassStFrwdBkwdPosMin2_Val: accessed-parameter=KeSMSw6SVIPMdPassStFrwdBkwdPosMin2.Val
            PA_KeSMSw6SVIPMdPassStFrwdBkwdPosPos_Val: accessed-parameter=KeSMSw6SVIPMdPassStFrwdBkwdPosPos.Val
            PA_KeSMSw6SVIPMdPassStFrwdBkwdPosPosMax_Val: accessed-parameter=KeSMSw6SVIPMdPassStFrwdBkwdPosPosMax.Val
            PA_KeSMSw6SVIPMdPassStFrwdBkwdPosPosMin_Val: accessed-parameter=KeSMSw6SVIPMdPassStFrwdBkwdPosPosMin.Val
            PA_KeSMSwAcsEntryPassStBkReclnUpwdDnwdPos_Val: accessed-parameter=KeSMSwAcsEntryPassStBkReclnUpwdDnwdPos.Val
            PA_KeSMSwAcsEntryPassStBkReclnUpwdDnwdPosMax_Val: accessed-parameter=KeSMSwAcsEntryPassStBkReclnUpwdDnwdPosMax.Val
            PA_KeSMSwAcsEntryPassStBkReclnUpwdDnwdPosMin_Val: accessed-parameter=KeSMSwAcsEntryPassStBkReclnUpwdDnwdPosMin.Val
            PA_KeSMSwAcsEntryPassStFrwdBkwdPos_Val: accessed-parameter=KeSMSwAcsEntryPassStFrwdBkwdPos.Val
            PA_KeSMSwAcsEntryPassStFrwdBkwdPosMax_Val: accessed-parameter=KeSMSwAcsEntryPassStFrwdBkwdPosMax.Val
            PA_KeSMSwAcsEntryPassStFrwdBkwdPosMin_Val: accessed-parameter=KeSMSwAcsEntryPassStFrwdBkwdPosMin.Val
            PA_KeSMSwAcsEntryPassStFtUpwdDnwdPos_Val: accessed-parameter=KeSMSwAcsEntryPassStFtUpwdDnwdPos.Val
            PA_KeSMSwAcsEntryPassStFtUpwdDnwdPosMiax_Val: accessed-parameter=KeSMSwAcsEntryPassStFtUpwdDnwdPosMiax.Val
            PA_KeSMSwAcsEntryPassStFtUpwdDnwdPosMin_Val: accessed-parameter=KeSMSwAcsEntryPassStFtUpwdDnwdPosMin.Val
            PA_KeSMSwAcsExtPassStFtUpwdDnwdPos_Val: accessed-parameter=KeSMSwAcsExtPassStFtUpwdDnwdPos.Val
            PA_KeSMSwAcsExtPassStFtUpwdDnwdPosMax_Val: accessed-parameter=KeSMSwAcsExtPassStFtUpwdDnwdPosMax.Val
            PA_KeSMSwAcsExtPassStFtUpwdDnwdPosMin_Val: accessed-parameter=KeSMSwAcsExtPassStFtUpwdDnwdPosMin.Val
            PA_KeSMSwAcsMd30PassStBkReclnUpwdDnwdPos_Val: accessed-parameter=KeSMSwAcsMd30PassStBkReclnUpwdDnwdPos.Val
            PA_KeSMSwAcsMd30PassStBkReclnUpwdDnwdPos1_Val: accessed-parameter=KeSMSwAcsMd30PassStBkReclnUpwdDnwdPos1.Val
            PA_KeSMSwAcsMd30PassStBkReclnUpwdDnwdPos1Max_Val: accessed-parameter=KeSMSwAcsMd30PassStBkReclnUpwdDnwdPos1Max.Val
            PA_KeSMSwAcsMd30PassStBkReclnUpwdDnwdPos1Min_Val: accessed-parameter=KeSMSwAcsMd30PassStBkReclnUpwdDnwdPos1Min.Val
            PA_KeSMSwAcsMd30PassStBkReclnUpwdDnwdPosMax_Val: accessed-parameter=KeSMSwAcsMd30PassStBkReclnUpwdDnwdPosMax.Val
            PA_KeSMSwAcsMd30PassStBkReclnUpwdDnwdPosMin_Val: accessed-parameter=KeSMSwAcsMd30PassStBkReclnUpwdDnwdPosMin.Val
            PA_KeSMSwAcsMd30PassStFldUpwdDnwdPos_Val: accessed-parameter=KeSMSwAcsMd30PassStFldUpwdDnwdPos.Val
            PA_KeSMSwAcsMd30PassStFldUpwdDnwdPos1_Val: accessed-parameter=KeSMSwAcsMd30PassStFldUpwdDnwdPos1.Val
            PA_KeSMSwAcsMd30PassStFldUpwdDnwdPos1Max_Val: accessed-parameter=KeSMSwAcsMd30PassStFldUpwdDnwdPos1Max.Val
            PA_KeSMSwAcsMd30PassStFldUpwdDnwdPos1Min_Val: accessed-parameter=KeSMSwAcsMd30PassStFldUpwdDnwdPos1Min.Val
            PA_KeSMSwAcsMd30PassStFldUpwdDnwdPosMax_Val: accessed-parameter=KeSMSwAcsMd30PassStFldUpwdDnwdPosMax.Val
            PA_KeSMSwAcsMd30PassStFldUpwdDnwdPosMin_Val: accessed-parameter=KeSMSwAcsMd30PassStFldUpwdDnwdPosMin.Val
            PA_KeSMSwAcsMd30PassStFrwdBkwdPos_Val: accessed-parameter=KeSMSwAcsMd30PassStFrwdBkwdPos.Val
            PA_KeSMSwAcsMd30PassStFrwdBkwdPos1_Val: accessed-parameter=KeSMSwAcsMd30PassStFrwdBkwdPos1.Val
            PA_KeSMSwAcsMd30PassStFrwdBkwdPos1Max_Val: accessed-parameter=KeSMSwAcsMd30PassStFrwdBkwdPos1Max.Val
            PA_KeSMSwAcsMd30PassStFrwdBkwdPos1Min_Val: accessed-parameter=KeSMSwAcsMd30PassStFrwdBkwdPos1Min.Val
            PA_KeSMSwAcsMd30PassStFrwdBkwdPosMax_Val: accessed-parameter=KeSMSwAcsMd30PassStFrwdBkwdPosMax.Val
            PA_KeSMSwAcsMd30PassStFrwdBkwdPosMin_Val: accessed-parameter=KeSMSwAcsMd30PassStFrwdBkwdPosMin.Val
            PA_KeSMSwAcsMd31PassStBkReclnUpwdDnwdPos_Val: accessed-parameter=KeSMSwAcsMd31PassStBkReclnUpwdDnwdPos.Val
            PA_KeSMSwAcsMd31PassStBkReclnUpwdDnwdPos1_Val: accessed-parameter=KeSMSwAcsMd31PassStBkReclnUpwdDnwdPos1.Val
            PA_KeSMSwAcsMd31PassStBkReclnUpwdDnwdPos1Max_Val: accessed-parameter=KeSMSwAcsMd31PassStBkReclnUpwdDnwdPos1Max.Val
            PA_KeSMSwAcsMd31PassStBkReclnUpwdDnwdPos1Min_Val: accessed-parameter=KeSMSwAcsMd31PassStBkReclnUpwdDnwdPos1Min.Val
            PA_KeSMSwAcsMd31PassStBkReclnUpwdDnwdPosMax_Val: accessed-parameter=KeSMSwAcsMd31PassStBkReclnUpwdDnwdPosMax.Val
            PA_KeSMSwAcsMd31PassStBkReclnUpwdDnwdPosMin_Val: accessed-parameter=KeSMSwAcsMd31PassStBkReclnUpwdDnwdPosMin.Val
            PA_KeSMSwAcsMd31PassStFldUpwdDnwdPos_Val: accessed-parameter=KeSMSwAcsMd31PassStFldUpwdDnwdPos.Val
            PA_KeSMSwAcsMd31PassStFldUpwdDnwdPosMax_Val: accessed-parameter=KeSMSwAcsMd31PassStFldUpwdDnwdPosMax.Val
            PA_KeSMSwAcsMd31PassStFldUpwdDnwdPosMin_Val: accessed-parameter=KeSMSwAcsMd31PassStFldUpwdDnwdPosMin.Val
            PA_KeSMSwAcsMd31PassStFrwdBkwdPos_Val: accessed-parameter=KeSMSwAcsMd31PassStFrwdBkwdPos.Val
            PA_KeSMSwAcsMd31PassStFrwdBkwdPos1_Val: accessed-parameter=KeSMSwAcsMd31PassStFrwdBkwdPos1.Val
            PA_KeSMSwAcsMd31PassStFrwdBkwdPos1Max_Val: accessed-parameter=KeSMSwAcsMd31PassStFrwdBkwdPos1Max.Val
            PA_KeSMSwAcsMd31PassStFrwdBkwdPos1Min_Val: accessed-parameter=KeSMSwAcsMd31PassStFrwdBkwdPos1Min.Val
            PA_KeSMSwAcsMd31PassStFrwdBkwdPosMax_Val: accessed-parameter=KeSMSwAcsMd31PassStFrwdBkwdPosMax.Val
            PA_KeSMSwAcsMd31PassStFrwdBkwdPosMin_Val: accessed-parameter=KeSMSwAcsMd31PassStFrwdBkwdPosMin.Val
            PA_KeSMSwAcsMd56PassStBkReclnUpwdDnwdPos_Val: accessed-parameter=KeSMSwAcsMd56PassStBkReclnUpwdDnwdPos.Val
            PA_KeSMSwAcsMd56PassStBkReclnUpwdDnwdPosMax_Val: accessed-parameter=KeSMSwAcsMd56PassStBkReclnUpwdDnwdPosMax.Val
            PA_KeSMSwAcsMd56PassStBkReclnUpwdDnwdPosMin_Val: accessed-parameter=KeSMSwAcsMd56PassStBkReclnUpwdDnwdPosMin.Val
            PA_KeSMSwAcsMd56PassStFrwdBkwdPos_Val: accessed-parameter=KeSMSwAcsMd56PassStFrwdBkwdPos.Val
            PA_KeSMSwAcsMd56PassStFrwdBkwdPosMax_Val: accessed-parameter=KeSMSwAcsMd56PassStFrwdBkwdPosMax.Val
            PA_KeSMSwAcsMd56PassStFrwdBkwdPosMin_Val: accessed-parameter=KeSMSwAcsMd56PassStFrwdBkwdPosMin.Val
            PA_KeSMSwAcsMd57PassStBkReclnUpwdDnwdPosPos_Val: accessed-parameter=KeSMSwAcsMd57PassStBkReclnUpwdDnwdPosPos.Val
            PA_KeSMSwAcsMd57PassStBkReclnUpwdDnwdPosPosMax_Val: accessed-parameter=KeSMSwAcsMd57PassStBkReclnUpwdDnwdPosPosMax.Val
            PA_KeSMSwAcsMd57PassStBkReclnUpwdDnwdPosPosMin_Val: accessed-parameter=KeSMSwAcsMd57PassStBkReclnUpwdDnwdPosPosMin.Val
            PA_KeSMSwAcsMd57PassStFoldFwdBkwdPosPos_Val: accessed-parameter=KeSMSwAcsMd57PassStFoldFwdBkwdPosPos.Val
            PA_KeSMSwAcsMd57PassStFoldFwdBkwdPosPos1_Val: accessed-parameter=KeSMSwAcsMd57PassStFoldFwdBkwdPosPos1.Val
            PA_KeSMSwAcsMd57PassStFoldFwdBkwdPosPos1Max_Val: accessed-parameter=KeSMSwAcsMd57PassStFoldFwdBkwdPosPos1Max.Val
            PA_KeSMSwAcsMd57PassStFoldFwdBkwdPosPos1Min_Val: accessed-parameter=KeSMSwAcsMd57PassStFoldFwdBkwdPosPos1Min.Val
            PA_KeSMSwAcsMd57PassStFoldFwdBkwdPosPosMax_Val: accessed-parameter=KeSMSwAcsMd57PassStFoldFwdBkwdPosPosMax.Val
            PA_KeSMSwAcsMd57PassStFoldFwdBkwdPosPosMin_Val: accessed-parameter=KeSMSwAcsMd57PassStFoldFwdBkwdPosPosMin.Val
            PA_KeSMSwAcsMd57PassStFrwdBkwdPosPos1_Val: accessed-parameter=KeSMSwAcsMd57PassStFrwdBkwdPosPos1.Val
            PA_KeSMSwAcsMd57PassStFrwdBkwdPosPos1Max_Val: accessed-parameter=KeSMSwAcsMd57PassStFrwdBkwdPosPos1Max.Val
            PA_KeSMSwAcsMd57PassStFrwdBkwdPosPos1Min_Val: accessed-parameter=KeSMSwAcsMd57PassStFrwdBkwdPosPos1Min.Val
            PA_KeSMSwAcsMd57PassStFrwdBkwdPosPos2_Val: accessed-parameter=KeSMSwAcsMd57PassStFrwdBkwdPosPos2.Val
            PA_KeSMSwAcsMd57PassStFrwdBkwdPosPos2Max_Val: accessed-parameter=KeSMSwAcsMd57PassStFrwdBkwdPosPos2Max.Val
            PA_KeSMSwAcsMd57PassStFrwdBkwdPosPos2Min_Val: accessed-parameter=KeSMSwAcsMd57PassStFrwdBkwdPosPos2Min.Val
            PA_KeSMSwAcsMd58PassStBkReclnUpwdDnwdPosPos1_Val: accessed-parameter=KeSMSwAcsMd58PassStBkReclnUpwdDnwdPosPos1.Val
            PA_KeSMSwAcsMd58PassStBkReclnUpwdDnwdPosPos1Max_Val: accessed-parameter=KeSMSwAcsMd58PassStBkReclnUpwdDnwdPosPos1Max.Val
            PA_KeSMSwAcsMd58PassStBkReclnUpwdDnwdPosPos1Min_Val: accessed-parameter=KeSMSwAcsMd58PassStBkReclnUpwdDnwdPosPos1Min.Val
            PA_KeSMSwAcsMd58PassStFrwdBkwdPosPos1_Val: accessed-parameter=KeSMSwAcsMd58PassStFrwdBkwdPosPos1.Val
            PA_KeSMSwAcsMd58PassStFrwdBkwdPosPos1Max_Val: accessed-parameter=KeSMSwAcsMd58PassStFrwdBkwdPosPos1Max.Val
            PA_KeSMSwAcsMd58PassStFrwdBkwdPosPos1Min_Val: accessed-parameter=KeSMSwAcsMd58PassStFrwdBkwdPosPos1Min.Val
            PA_KeSMSwPassStBkReclnEnTrig557BitMask_Val: accessed-parameter=KeSMSwPassStBkReclnEnTrig557BitMask.Val
            PA_KeSMSwPassStCshnFldEnTrig557BitMask_Val: accessed-parameter=KeSMSwPassStCshnFldEnTrig557BitMask.Val
            PA_KeSMSwPassStFwdBkwdEnTrig557BitMask_Val: accessed-parameter=KeSMSwPassStFwdBkwdEnTrig557BitMask.Val
            PA_KeSMSwRecoveryPassStStFtUpwdDnwdPos_Val: accessed-parameter=KeSMSwRecoveryPassStStFtUpwdDnwdPos.Val
            PA_KeSMSwRecoveryPassStStFtUpwdDnwdPosMax_Val: accessed-parameter=KeSMSwRecoveryPassStStFtUpwdDnwdPosMax.Val
            PA_KeSMSwRecoveryPassStStFtUpwdDnwdPosMin_Val: accessed-parameter=KeSMSwRecoveryPassStStFtUpwdDnwdPosMin.Val
            PA_KeSMSwRevRMDPassStBkReclnUpwdDnwdPos_Val: accessed-parameter=KeSMSwRevRMDPassStBkReclnUpwdDnwdPos.Val
            PA_KeSMSwRevRMDPassStBkReclnUpwdDnwdPosMax_Val: accessed-parameter=KeSMSwRevRMDPassStBkReclnUpwdDnwdPosMax.Val
            PA_KeSMSwRevRMDPassStBkReclnUpwdDnwdPosMin_Val: accessed-parameter=KeSMSwRevRMDPassStBkReclnUpwdDnwdPosMin.Val
            PA_KeSMSwRevRMDPassStFrwdBkwdPos_Val: accessed-parameter=KeSMSwRevRMDPassStFrwdBkwdPos.Val
            PA_KeSMSwRevRMDPassStFrwdBkwdPosMax_Val: accessed-parameter=KeSMSwRevRMDPassStFrwdBkwdPosMax.Val
            PA_KeSMSwRevRMDPassStFrwdBkwdPosMin_Val: accessed-parameter=KeSMSwRevRMDPassStFrwdBkwdPosMin.Val
            PA_KeSMSwVIPMDPassStBkReclnUpwdDnwdPosPos_Val: accessed-parameter=KeSMSwVIPMDPassStBkReclnUpwdDnwdPosPos.Val
            PA_KeSMSwVIPMDPassStBkReclnUpwdDnwdPosPosMax_Val: accessed-parameter=KeSMSwVIPMDPassStBkReclnUpwdDnwdPosPosMax.Val
            PA_KeSMSwVIPMDPassStBkReclnUpwdDnwdPosPosMin_Val: accessed-parameter=KeSMSwVIPMDPassStBkReclnUpwdDnwdPosPosMin.Val
            PA_KeSMSwVIPMDPassStFrwdBkwdPos2_Val: accessed-parameter=KeSMSwVIPMDPassStFrwdBkwdPos2.Val
            PA_KeSMSwVIPMDPassStFrwdBkwdPosMax2_Val: accessed-parameter=KeSMSwVIPMDPassStFrwdBkwdPosMax2.Val
            PA_KeSMSwVIPMDPassStFrwdBkwdPosMin2_Val: accessed-parameter=KeSMSwVIPMDPassStFrwdBkwdPosMin2.Val
            PA_KeSMSwVIPMDPassStFrwdBkwdPosPos_Val: accessed-parameter=KeSMSwVIPMDPassStFrwdBkwdPosPos.Val
            PA_KeSMSwVIPMDPassStFrwdBkwdPosPosMax_Val: accessed-parameter=KeSMSwVIPMDPassStFrwdBkwdPosPosMax.Val
            PA_KeSMSwVIPMDPassStFrwdBkwdPosPosMin_Val: accessed-parameter=KeSMSwVIPMDPassStFrwdBkwdPosPosMin.Val
        PassStCshnFldTrgtPosSelc_1_Cal
          data-send-points:
            7 x access:
              SEND_Md30PassStCshnFldTrgtPosCalib_TrgtPosArray: accessed-variable=Md30PassStCshnFldTrgtPosCalib.TrgtPosArray
              SEND_Md30PassStCshnFldTrgtPosCalib1_TrgtPosArray: accessed-variable=Md30PassStCshnFldTrgtPosCalib1.TrgtPosArray
              SEND_Md31PassStCshnFldTrgtPosCalib_TrgtPosArray: accessed-variable=Md31PassStCshnFldTrgtPosCalib.TrgtPosArray
              SEND_Md57PassStCshnFldTrgtPosCalib_TrgtPosArray: accessed-variable=Md57PassStCshnFldTrgtPosCalib.TrgtPosArray
              SEND_Md57PassStCshnFldTrgtPosCalib1_TrgtPosArray: accessed-variable=Md57PassStCshnFldTrgtPosCalib1.TrgtPosArray
              SEND_Md58PassStCshnFldTrgtPosCalib_TrgtPosArray: accessed-variable=Md58PassStCshnFldTrgtPosCalib.TrgtPosArray
              SEND_PassStCshnFldStEnTrigBitMask_Val: accessed-variable=PassStCshnFldStEnTrigBitMask.Val
          112 x parameter access:
            PA_KeSMSuSecRwStVIPFtrstRefAngle_Val: accessed-parameter=KeSMSuSecRwStVIPFtrstRefAngle.Val
            PA_KeSMSw6sAcsEntryPassStFtUpwdDnwdPos_Val: accessed-parameter=KeSMSw6sAcsEntryPassStFtUpwdDnwdPos.Val
            PA_KeSMSw6sAcsEntryPassStFtUpwdDnwdPosMiax_Val: accessed-parameter=KeSMSw6sAcsEntryPassStFtUpwdDnwdPosMiax.Val
            PA_KeSMSw6sAcsEntryPassStFtUpwdDnwdPosMin_Val: accessed-parameter=KeSMSw6sAcsEntryPassStFtUpwdDnwdPosMin.Val
            PA_KeSMSw6sAcsExtPassStFtUpwdDnwdPos_Val: accessed-parameter=KeSMSw6sAcsExtPassStFtUpwdDnwdPos.Val
            PA_KeSMSw6sAcsExtPassStFtUpwdDnwdPosMax_Val: accessed-parameter=KeSMSw6sAcsExtPassStFtUpwdDnwdPosMax.Val
            PA_KeSMSw6sAcsExtPassStFtUpwdDnwdPosMin_Val: accessed-parameter=KeSMSw6sAcsExtPassStFtUpwdDnwdPosMin.Val
            PA_KeSMSw6sRecoveryPassStStFtUpwdDnwdPos_Val: accessed-parameter=KeSMSw6sRecoveryPassStStFtUpwdDnwdPos.Val
            PA_KeSMSw6sRecoveryPassStStFtUpwdDnwdPosMax_Val: accessed-parameter=KeSMSw6sRecoveryPassStStFtUpwdDnwdPosMax.Val
            PA_KeSMSw6sRecoveryPassStStFtUpwdDnwdPosMin_Val: accessed-parameter=KeSMSw6sRecoveryPassStStFtUpwdDnwdPosMin.Val
            PA_KeSMSw6SVIPMdPassStBkReclnUpwdDnwdPosPos_Val: accessed-parameter=KeSMSw6SVIPMdPassStBkReclnUpwdDnwdPosPos.Val
            PA_KeSMSw6SVIPMdPassStBkReclnUpwdDnwdPosPosMax_Val: accessed-parameter=KeSMSw6SVIPMdPassStBkReclnUpwdDnwdPosPosMax.Val
            PA_KeSMSw6SVIPMdPassStBkReclnUpwdDnwdPosPosMin_Val: accessed-parameter=KeSMSw6SVIPMdPassStBkReclnUpwdDnwdPosPosMin.Val
            PA_KeSMSw6SVIPMdPassStFrwdBkwdPos2_Val: accessed-parameter=KeSMSw6SVIPMdPassStFrwdBkwdPos2.Val
            PA_KeSMSw6SVIPMdPassStFrwdBkwdPosMax2_Val: accessed-parameter=KeSMSw6SVIPMdPassStFrwdBkwdPosMax2.Val
            PA_KeSMSw6SVIPMdPassStFrwdBkwdPosMin2_Val: accessed-parameter=KeSMSw6SVIPMdPassStFrwdBkwdPosMin2.Val
            PA_KeSMSw6SVIPMdPassStFrwdBkwdPosPos_Val: accessed-parameter=KeSMSw6SVIPMdPassStFrwdBkwdPosPos.Val
            PA_KeSMSw6SVIPMdPassStFrwdBkwdPosPosMax_Val: accessed-parameter=KeSMSw6SVIPMdPassStFrwdBkwdPosPosMax.Val
            PA_KeSMSw6SVIPMdPassStFrwdBkwdPosPosMin_Val: accessed-parameter=KeSMSw6SVIPMdPassStFrwdBkwdPosPosMin.Val
            PA_KeSMSwAcsEntryPassStBkReclnUpwdDnwdPos_Val: accessed-parameter=KeSMSwAcsEntryPassStBkReclnUpwdDnwdPos.Val
            PA_KeSMSwAcsEntryPassStBkReclnUpwdDnwdPosMax_Val: accessed-parameter=KeSMSwAcsEntryPassStBkReclnUpwdDnwdPosMax.Val
            PA_KeSMSwAcsEntryPassStBkReclnUpwdDnwdPosMin_Val: accessed-parameter=KeSMSwAcsEntryPassStBkReclnUpwdDnwdPosMin.Val
            PA_KeSMSwAcsEntryPassStFrwdBkwdPos_Val: accessed-parameter=KeSMSwAcsEntryPassStFrwdBkwdPos.Val
            PA_KeSMSwAcsEntryPassStFrwdBkwdPosMax_Val: accessed-parameter=KeSMSwAcsEntryPassStFrwdBkwdPosMax.Val
            PA_KeSMSwAcsEntryPassStFrwdBkwdPosMin_Val: accessed-parameter=KeSMSwAcsEntryPassStFrwdBkwdPosMin.Val
            PA_KeSMSwAcsEntryPassStFtUpwdDnwdPos_Val: accessed-parameter=KeSMSwAcsEntryPassStFtUpwdDnwdPos.Val
            PA_KeSMSwAcsEntryPassStFtUpwdDnwdPosMiax_Val: accessed-parameter=KeSMSwAcsEntryPassStFtUpwdDnwdPosMiax.Val
            PA_KeSMSwAcsEntryPassStFtUpwdDnwdPosMin_Val: accessed-parameter=KeSMSwAcsEntryPassStFtUpwdDnwdPosMin.Val
            PA_KeSMSwAcsExtPassStFtUpwdDnwdPos_Val: accessed-parameter=KeSMSwAcsExtPassStFtUpwdDnwdPos.Val
            PA_KeSMSwAcsExtPassStFtUpwdDnwdPosMax_Val: accessed-parameter=KeSMSwAcsExtPassStFtUpwdDnwdPosMax.Val
            PA_KeSMSwAcsExtPassStFtUpwdDnwdPosMin_Val: accessed-parameter=KeSMSwAcsExtPassStFtUpwdDnwdPosMin.Val
            PA_KeSMSwAcsMd30PassStBkReclnUpwdDnwdPos_Val: accessed-parameter=KeSMSwAcsMd30PassStBkReclnUpwdDnwdPos.Val
            PA_KeSMSwAcsMd30PassStBkReclnUpwdDnwdPos1_Val: accessed-parameter=KeSMSwAcsMd30PassStBkReclnUpwdDnwdPos1.Val
            PA_KeSMSwAcsMd30PassStBkReclnUpwdDnwdPos1Max_Val: accessed-parameter=KeSMSwAcsMd30PassStBkReclnUpwdDnwdPos1Max.Val
            PA_KeSMSwAcsMd30PassStBkReclnUpwdDnwdPos1Min_Val: accessed-parameter=KeSMSwAcsMd30PassStBkReclnUpwdDnwdPos1Min.Val
            PA_KeSMSwAcsMd30PassStBkReclnUpwdDnwdPosMax_Val: accessed-parameter=KeSMSwAcsMd30PassStBkReclnUpwdDnwdPosMax.Val
            PA_KeSMSwAcsMd30PassStBkReclnUpwdDnwdPosMin_Val: accessed-parameter=KeSMSwAcsMd30PassStBkReclnUpwdDnwdPosMin.Val
            PA_KeSMSwAcsMd30PassStFldUpwdDnwdPos_Val: accessed-parameter=KeSMSwAcsMd30PassStFldUpwdDnwdPos.Val
            PA_KeSMSwAcsMd30PassStFldUpwdDnwdPos1_Val: accessed-parameter=KeSMSwAcsMd30PassStFldUpwdDnwdPos1.Val
            PA_KeSMSwAcsMd30PassStFldUpwdDnwdPos1Max_Val: accessed-parameter=KeSMSwAcsMd30PassStFldUpwdDnwdPos1Max.Val
            PA_KeSMSwAcsMd30PassStFldUpwdDnwdPos1Min_Val: accessed-parameter=KeSMSwAcsMd30PassStFldUpwdDnwdPos1Min.Val
            PA_KeSMSwAcsMd30PassStFldUpwdDnwdPosMax_Val: accessed-parameter=KeSMSwAcsMd30PassStFldUpwdDnwdPosMax.Val
            PA_KeSMSwAcsMd30PassStFldUpwdDnwdPosMin_Val: accessed-parameter=KeSMSwAcsMd30PassStFldUpwdDnwdPosMin.Val
            PA_KeSMSwAcsMd30PassStFrwdBkwdPos_Val: accessed-parameter=KeSMSwAcsMd30PassStFrwdBkwdPos.Val
            PA_KeSMSwAcsMd30PassStFrwdBkwdPos1_Val: accessed-parameter=KeSMSwAcsMd30PassStFrwdBkwdPos1.Val
            PA_KeSMSwAcsMd30PassStFrwdBkwdPos1Max_Val: accessed-parameter=KeSMSwAcsMd30PassStFrwdBkwdPos1Max.Val
            PA_KeSMSwAcsMd30PassStFrwdBkwdPos1Min_Val: accessed-parameter=KeSMSwAcsMd30PassStFrwdBkwdPos1Min.Val
            PA_KeSMSwAcsMd30PassStFrwdBkwdPosMax_Val: accessed-parameter=KeSMSwAcsMd30PassStFrwdBkwdPosMax.Val
            PA_KeSMSwAcsMd30PassStFrwdBkwdPosMin_Val: accessed-parameter=KeSMSwAcsMd30PassStFrwdBkwdPosMin.Val
            PA_KeSMSwAcsMd31PassStBkReclnUpwdDnwdPos_Val: accessed-parameter=KeSMSwAcsMd31PassStBkReclnUpwdDnwdPos.Val
            PA_KeSMSwAcsMd31PassStBkReclnUpwdDnwdPos1_Val: accessed-parameter=KeSMSwAcsMd31PassStBkReclnUpwdDnwdPos1.Val
            PA_KeSMSwAcsMd31PassStBkReclnUpwdDnwdPos1Max_Val: accessed-parameter=KeSMSwAcsMd31PassStBkReclnUpwdDnwdPos1Max.Val
            PA_KeSMSwAcsMd31PassStBkReclnUpwdDnwdPos1Min_Val: accessed-parameter=KeSMSwAcsMd31PassStBkReclnUpwdDnwdPos1Min.Val
            PA_KeSMSwAcsMd31PassStBkReclnUpwdDnwdPosMax_Val: accessed-parameter=KeSMSwAcsMd31PassStBkReclnUpwdDnwdPosMax.Val
            PA_KeSMSwAcsMd31PassStBkReclnUpwdDnwdPosMin_Val: accessed-parameter=KeSMSwAcsMd31PassStBkReclnUpwdDnwdPosMin.Val
            PA_KeSMSwAcsMd31PassStFldUpwdDnwdPos_Val: accessed-parameter=KeSMSwAcsMd31PassStFldUpwdDnwdPos.Val
            PA_KeSMSwAcsMd31PassStFldUpwdDnwdPosMax_Val: accessed-parameter=KeSMSwAcsMd31PassStFldUpwdDnwdPosMax.Val
            PA_KeSMSwAcsMd31PassStFldUpwdDnwdPosMin_Val: accessed-parameter=KeSMSwAcsMd31PassStFldUpwdDnwdPosMin.Val
            PA_KeSMSwAcsMd31PassStFrwdBkwdPos_Val: accessed-parameter=KeSMSwAcsMd31PassStFrwdBkwdPos.Val
            PA_KeSMSwAcsMd31PassStFrwdBkwdPos1_Val: accessed-parameter=KeSMSwAcsMd31PassStFrwdBkwdPos1.Val
            PA_KeSMSwAcsMd31PassStFrwdBkwdPos1Max_Val: accessed-parameter=KeSMSwAcsMd31PassStFrwdBkwdPos1Max.Val
            PA_KeSMSwAcsMd31PassStFrwdBkwdPos1Min_Val: accessed-parameter=KeSMSwAcsMd31PassStFrwdBkwdPos1Min.Val
            PA_KeSMSwAcsMd31PassStFrwdBkwdPosMax_Val: accessed-parameter=KeSMSwAcsMd31PassStFrwdBkwdPosMax.Val
            PA_KeSMSwAcsMd31PassStFrwdBkwdPosMin_Val: accessed-parameter=KeSMSwAcsMd31PassStFrwdBkwdPosMin.Val
            PA_KeSMSwAcsMd56PassStBkReclnUpwdDnwdPos_Val: accessed-parameter=KeSMSwAcsMd56PassStBkReclnUpwdDnwdPos.Val
            PA_KeSMSwAcsMd56PassStBkReclnUpwdDnwdPosMax_Val: accessed-parameter=KeSMSwAcsMd56PassStBkReclnUpwdDnwdPosMax.Val
            PA_KeSMSwAcsMd56PassStBkReclnUpwdDnwdPosMin_Val: accessed-parameter=KeSMSwAcsMd56PassStBkReclnUpwdDnwdPosMin.Val
            PA_KeSMSwAcsMd56PassStFrwdBkwdPos_Val: accessed-parameter=KeSMSwAcsMd56PassStFrwdBkwdPos.Val
            PA_KeSMSwAcsMd56PassStFrwdBkwdPosMax_Val: accessed-parameter=KeSMSwAcsMd56PassStFrwdBkwdPosMax.Val
            PA_KeSMSwAcsMd56PassStFrwdBkwdPosMin_Val: accessed-parameter=KeSMSwAcsMd56PassStFrwdBkwdPosMin.Val
            PA_KeSMSwAcsMd57PassStBkReclnUpwdDnwdPosPos_Val: accessed-parameter=KeSMSwAcsMd57PassStBkReclnUpwdDnwdPosPos.Val
            PA_KeSMSwAcsMd57PassStBkReclnUpwdDnwdPosPosMax_Val: accessed-parameter=KeSMSwAcsMd57PassStBkReclnUpwdDnwdPosPosMax.Val
            PA_KeSMSwAcsMd57PassStBkReclnUpwdDnwdPosPosMin_Val: accessed-parameter=KeSMSwAcsMd57PassStBkReclnUpwdDnwdPosPosMin.Val
            PA_KeSMSwAcsMd57PassStFoldFwdBkwdPosPos_Val: accessed-parameter=KeSMSwAcsMd57PassStFoldFwdBkwdPosPos.Val
            PA_KeSMSwAcsMd57PassStFoldFwdBkwdPosPos1_Val: accessed-parameter=KeSMSwAcsMd57PassStFoldFwdBkwdPosPos1.Val
            PA_KeSMSwAcsMd57PassStFoldFwdBkwdPosPos1Max_Val: accessed-parameter=KeSMSwAcsMd57PassStFoldFwdBkwdPosPos1Max.Val
            PA_KeSMSwAcsMd57PassStFoldFwdBkwdPosPos1Min_Val: accessed-parameter=KeSMSwAcsMd57PassStFoldFwdBkwdPosPos1Min.Val
            PA_KeSMSwAcsMd57PassStFoldFwdBkwdPosPosMax_Val: accessed-parameter=KeSMSwAcsMd57PassStFoldFwdBkwdPosPosMax.Val
            PA_KeSMSwAcsMd57PassStFoldFwdBkwdPosPosMin_Val: accessed-parameter=KeSMSwAcsMd57PassStFoldFwdBkwdPosPosMin.Val
            PA_KeSMSwAcsMd57PassStFrwdBkwdPosPos1_Val: accessed-parameter=KeSMSwAcsMd57PassStFrwdBkwdPosPos1.Val
            PA_KeSMSwAcsMd57PassStFrwdBkwdPosPos1Max_Val: accessed-parameter=KeSMSwAcsMd57PassStFrwdBkwdPosPos1Max.Val
            PA_KeSMSwAcsMd57PassStFrwdBkwdPosPos1Min_Val: accessed-parameter=KeSMSwAcsMd57PassStFrwdBkwdPosPos1Min.Val
            PA_KeSMSwAcsMd57PassStFrwdBkwdPosPos2_Val: accessed-parameter=KeSMSwAcsMd57PassStFrwdBkwdPosPos2.Val
            PA_KeSMSwAcsMd57PassStFrwdBkwdPosPos2Max_Val: accessed-parameter=KeSMSwAcsMd57PassStFrwdBkwdPosPos2Max.Val
            PA_KeSMSwAcsMd57PassStFrwdBkwdPosPos2Min_Val: accessed-parameter=KeSMSwAcsMd57PassStFrwdBkwdPosPos2Min.Val
            PA_KeSMSwAcsMd58PassStBkReclnUpwdDnwdPosPos1_Val: accessed-parameter=KeSMSwAcsMd58PassStBkReclnUpwdDnwdPosPos1.Val
            PA_KeSMSwAcsMd58PassStBkReclnUpwdDnwdPosPos1Max_Val: accessed-parameter=KeSMSwAcsMd58PassStBkReclnUpwdDnwdPosPos1Max.Val
            PA_KeSMSwAcsMd58PassStBkReclnUpwdDnwdPosPos1Min_Val: accessed-parameter=KeSMSwAcsMd58PassStBkReclnUpwdDnwdPosPos1Min.Val
            PA_KeSMSwAcsMd58PassStFrwdBkwdPosPos1_Val: accessed-parameter=KeSMSwAcsMd58PassStFrwdBkwdPosPos1.Val
            PA_KeSMSwAcsMd58PassStFrwdBkwdPosPos1Max_Val: accessed-parameter=KeSMSwAcsMd58PassStFrwdBkwdPosPos1Max.Val
            PA_KeSMSwAcsMd58PassStFrwdBkwdPosPos1Min_Val: accessed-parameter=KeSMSwAcsMd58PassStFrwdBkwdPosPos1Min.Val
            PA_KeSMSwPassStBkReclnEnTrig557BitMask_Val: accessed-parameter=KeSMSwPassStBkReclnEnTrig557BitMask.Val
            PA_KeSMSwPassStCshnFldEnTrig557BitMask_Val: accessed-parameter=KeSMSwPassStCshnFldEnTrig557BitMask.Val
            PA_KeSMSwPassStFwdBkwdEnTrig557BitMask_Val: accessed-parameter=KeSMSwPassStFwdBkwdEnTrig557BitMask.Val
            PA_KeSMSwRecoveryPassStStFtUpwdDnwdPos_Val: accessed-parameter=KeSMSwRecoveryPassStStFtUpwdDnwdPos.Val
            PA_KeSMSwRecoveryPassStStFtUpwdDnwdPosMax_Val: accessed-parameter=KeSMSwRecoveryPassStStFtUpwdDnwdPosMax.Val
            PA_KeSMSwRecoveryPassStStFtUpwdDnwdPosMin_Val: accessed-parameter=KeSMSwRecoveryPassStStFtUpwdDnwdPosMin.Val
            PA_KeSMSwRevRMDPassStBkReclnUpwdDnwdPos_Val: accessed-parameter=KeSMSwRevRMDPassStBkReclnUpwdDnwdPos.Val
            PA_KeSMSwRevRMDPassStBkReclnUpwdDnwdPosMax_Val: accessed-parameter=KeSMSwRevRMDPassStBkReclnUpwdDnwdPosMax.Val
            PA_KeSMSwRevRMDPassStBkReclnUpwdDnwdPosMin_Val: accessed-parameter=KeSMSwRevRMDPassStBkReclnUpwdDnwdPosMin.Val
            PA_KeSMSwRevRMDPassStFrwdBkwdPos_Val: accessed-parameter=KeSMSwRevRMDPassStFrwdBkwdPos.Val
            PA_KeSMSwRevRMDPassStFrwdBkwdPosMax_Val: accessed-parameter=KeSMSwRevRMDPassStFrwdBkwdPosMax.Val
            PA_KeSMSwRevRMDPassStFrwdBkwdPosMin_Val: accessed-parameter=KeSMSwRevRMDPassStFrwdBkwdPosMin.Val
            PA_KeSMSwVIPMDPassStBkReclnUpwdDnwdPosPos_Val: accessed-parameter=KeSMSwVIPMDPassStBkReclnUpwdDnwdPosPos.Val
            PA_KeSMSwVIPMDPassStBkReclnUpwdDnwdPosPosMax_Val: accessed-parameter=KeSMSwVIPMDPassStBkReclnUpwdDnwdPosPosMax.Val
            PA_KeSMSwVIPMDPassStBkReclnUpwdDnwdPosPosMin_Val: accessed-parameter=KeSMSwVIPMDPassStBkReclnUpwdDnwdPosPosMin.Val
            PA_KeSMSwVIPMDPassStFrwdBkwdPos2_Val: accessed-parameter=KeSMSwVIPMDPassStFrwdBkwdPos2.Val
            PA_KeSMSwVIPMDPassStFrwdBkwdPosMax2_Val: accessed-parameter=KeSMSwVIPMDPassStFrwdBkwdPosMax2.Val
            PA_KeSMSwVIPMDPassStFrwdBkwdPosMin2_Val: accessed-parameter=KeSMSwVIPMDPassStFrwdBkwdPosMin2.Val
            PA_KeSMSwVIPMDPassStFrwdBkwdPosPos_Val: accessed-parameter=KeSMSwVIPMDPassStFrwdBkwdPosPos.Val
            PA_KeSMSwVIPMDPassStFrwdBkwdPosPosMax_Val: accessed-parameter=KeSMSwVIPMDPassStFrwdBkwdPosPosMax.Val
            PA_KeSMSwVIPMDPassStFrwdBkwdPosPosMin_Val: accessed-parameter=KeSMSwVIPMDPassStFrwdBkwdPosPosMin.Val
        PassStFtTrgtPosSelc_1_Cal
          data-receive-point-by-arguments:
            4 x access:
              REC_StNumFlg_Is4s: accessed-variable=StNumFlg.Is4s
              REC_StNumFlg_Is6s: accessed-variable=StNumFlg.Is6s
              REC_StNumFlg_Is6s7s: accessed-variable=StNumFlg.Is6s7s
              REC_StNumFlg_Is7s: accessed-variable=StNumFlg.Is7s
          data-send-points:
            4 x access:
              SEND_EZEPassStFtTrgtPosCalib_TrgtPosArray: accessed-variable=EZEPassStFtTrgtPosCalib.TrgtPosArray
              SEND_EZQPassStFtTrgtPosCalib_TrgtPosArray: accessed-variable=EZQPassStFtTrgtPosCalib.TrgtPosArray
              SEND_RecvRPassStFtTrgtPosCalib_TrgtPosArray: accessed-variable=RecvRPassStFtTrgtPosCalib.TrgtPosArray
              SEND_VIPRPassStFtTrgtPosCalib_TrgtPosArray: accessed-variable=VIPRPassStFtTrgtPosCalib.TrgtPosArray
          112 x parameter access:
            PA_KeSMSuSecRwStVIPFtrstRefAngle_Val: accessed-parameter=KeSMSuSecRwStVIPFtrstRefAngle.Val
            PA_KeSMSw6sAcsEntryPassStFtUpwdDnwdPos_Val: accessed-parameter=KeSMSw6sAcsEntryPassStFtUpwdDnwdPos.Val
            PA_KeSMSw6sAcsEntryPassStFtUpwdDnwdPosMiax_Val: accessed-parameter=KeSMSw6sAcsEntryPassStFtUpwdDnwdPosMiax.Val
            PA_KeSMSw6sAcsEntryPassStFtUpwdDnwdPosMin_Val: accessed-parameter=KeSMSw6sAcsEntryPassStFtUpwdDnwdPosMin.Val
            PA_KeSMSw6sAcsExtPassStFtUpwdDnwdPos_Val: accessed-parameter=KeSMSw6sAcsExtPassStFtUpwdDnwdPos.Val
            PA_KeSMSw6sAcsExtPassStFtUpwdDnwdPosMax_Val: accessed-parameter=KeSMSw6sAcsExtPassStFtUpwdDnwdPosMax.Val
            PA_KeSMSw6sAcsExtPassStFtUpwdDnwdPosMin_Val: accessed-parameter=KeSMSw6sAcsExtPassStFtUpwdDnwdPosMin.Val
            PA_KeSMSw6sRecoveryPassStStFtUpwdDnwdPos_Val: accessed-parameter=KeSMSw6sRecoveryPassStStFtUpwdDnwdPos.Val
            PA_KeSMSw6sRecoveryPassStStFtUpwdDnwdPosMax_Val: accessed-parameter=KeSMSw6sRecoveryPassStStFtUpwdDnwdPosMax.Val
            PA_KeSMSw6sRecoveryPassStStFtUpwdDnwdPosMin_Val: accessed-parameter=KeSMSw6sRecoveryPassStStFtUpwdDnwdPosMin.Val
            PA_KeSMSw6SVIPMdPassStBkReclnUpwdDnwdPosPos_Val: accessed-parameter=KeSMSw6SVIPMdPassStBkReclnUpwdDnwdPosPos.Val
            PA_KeSMSw6SVIPMdPassStBkReclnUpwdDnwdPosPosMax_Val: accessed-parameter=KeSMSw6SVIPMdPassStBkReclnUpwdDnwdPosPosMax.Val
            PA_KeSMSw6SVIPMdPassStBkReclnUpwdDnwdPosPosMin_Val: accessed-parameter=KeSMSw6SVIPMdPassStBkReclnUpwdDnwdPosPosMin.Val
            PA_KeSMSw6SVIPMdPassStFrwdBkwdPos2_Val: accessed-parameter=KeSMSw6SVIPMdPassStFrwdBkwdPos2.Val
            PA_KeSMSw6SVIPMdPassStFrwdBkwdPosMax2_Val: accessed-parameter=KeSMSw6SVIPMdPassStFrwdBkwdPosMax2.Val
            PA_KeSMSw6SVIPMdPassStFrwdBkwdPosMin2_Val: accessed-parameter=KeSMSw6SVIPMdPassStFrwdBkwdPosMin2.Val
            PA_KeSMSw6SVIPMdPassStFrwdBkwdPosPos_Val: accessed-parameter=KeSMSw6SVIPMdPassStFrwdBkwdPosPos.Val
            PA_KeSMSw6SVIPMdPassStFrwdBkwdPosPosMax_Val: accessed-parameter=KeSMSw6SVIPMdPassStFrwdBkwdPosPosMax.Val
            PA_KeSMSw6SVIPMdPassStFrwdBkwdPosPosMin_Val: accessed-parameter=KeSMSw6SVIPMdPassStFrwdBkwdPosPosMin.Val
            PA_KeSMSwAcsEntryPassStBkReclnUpwdDnwdPos_Val: accessed-parameter=KeSMSwAcsEntryPassStBkReclnUpwdDnwdPos.Val
            PA_KeSMSwAcsEntryPassStBkReclnUpwdDnwdPosMax_Val: accessed-parameter=KeSMSwAcsEntryPassStBkReclnUpwdDnwdPosMax.Val
            PA_KeSMSwAcsEntryPassStBkReclnUpwdDnwdPosMin_Val: accessed-parameter=KeSMSwAcsEntryPassStBkReclnUpwdDnwdPosMin.Val
            PA_KeSMSwAcsEntryPassStFrwdBkwdPos_Val: accessed-parameter=KeSMSwAcsEntryPassStFrwdBkwdPos.Val
            PA_KeSMSwAcsEntryPassStFrwdBkwdPosMax_Val: accessed-parameter=KeSMSwAcsEntryPassStFrwdBkwdPosMax.Val
            PA_KeSMSwAcsEntryPassStFrwdBkwdPosMin_Val: accessed-parameter=KeSMSwAcsEntryPassStFrwdBkwdPosMin.Val
            PA_KeSMSwAcsEntryPassStFtUpwdDnwdPos_Val: accessed-parameter=KeSMSwAcsEntryPassStFtUpwdDnwdPos.Val
            PA_KeSMSwAcsEntryPassStFtUpwdDnwdPosMiax_Val: accessed-parameter=KeSMSwAcsEntryPassStFtUpwdDnwdPosMiax.Val
            PA_KeSMSwAcsEntryPassStFtUpwdDnwdPosMin_Val: accessed-parameter=KeSMSwAcsEntryPassStFtUpwdDnwdPosMin.Val
            PA_KeSMSwAcsExtPassStFtUpwdDnwdPos_Val: accessed-parameter=KeSMSwAcsExtPassStFtUpwdDnwdPos.Val
            PA_KeSMSwAcsExtPassStFtUpwdDnwdPosMax_Val: accessed-parameter=KeSMSwAcsExtPassStFtUpwdDnwdPosMax.Val
            PA_KeSMSwAcsExtPassStFtUpwdDnwdPosMin_Val: accessed-parameter=KeSMSwAcsExtPassStFtUpwdDnwdPosMin.Val
            PA_KeSMSwAcsMd30PassStBkReclnUpwdDnwdPos_Val: accessed-parameter=KeSMSwAcsMd30PassStBkReclnUpwdDnwdPos.Val
            PA_KeSMSwAcsMd30PassStBkReclnUpwdDnwdPos1_Val: accessed-parameter=KeSMSwAcsMd30PassStBkReclnUpwdDnwdPos1.Val
            PA_KeSMSwAcsMd30PassStBkReclnUpwdDnwdPos1Max_Val: accessed-parameter=KeSMSwAcsMd30PassStBkReclnUpwdDnwdPos1Max.Val
            PA_KeSMSwAcsMd30PassStBkReclnUpwdDnwdPos1Min_Val: accessed-parameter=KeSMSwAcsMd30PassStBkReclnUpwdDnwdPos1Min.Val
            PA_KeSMSwAcsMd30PassStBkReclnUpwdDnwdPosMax_Val: accessed-parameter=KeSMSwAcsMd30PassStBkReclnUpwdDnwdPosMax.Val
            PA_KeSMSwAcsMd30PassStBkReclnUpwdDnwdPosMin_Val: accessed-parameter=KeSMSwAcsMd30PassStBkReclnUpwdDnwdPosMin.Val
            PA_KeSMSwAcsMd30PassStFldUpwdDnwdPos_Val: accessed-parameter=KeSMSwAcsMd30PassStFldUpwdDnwdPos.Val
            PA_KeSMSwAcsMd30PassStFldUpwdDnwdPos1_Val: accessed-parameter=KeSMSwAcsMd30PassStFldUpwdDnwdPos1.Val
            PA_KeSMSwAcsMd30PassStFldUpwdDnwdPos1Max_Val: accessed-parameter=KeSMSwAcsMd30PassStFldUpwdDnwdPos1Max.Val
            PA_KeSMSwAcsMd30PassStFldUpwdDnwdPos1Min_Val: accessed-parameter=KeSMSwAcsMd30PassStFldUpwdDnwdPos1Min.Val
            PA_KeSMSwAcsMd30PassStFldUpwdDnwdPosMax_Val: accessed-parameter=KeSMSwAcsMd30PassStFldUpwdDnwdPosMax.Val
            PA_KeSMSwAcsMd30PassStFldUpwdDnwdPosMin_Val: accessed-parameter=KeSMSwAcsMd30PassStFldUpwdDnwdPosMin.Val
            PA_KeSMSwAcsMd30PassStFrwdBkwdPos_Val: accessed-parameter=KeSMSwAcsMd30PassStFrwdBkwdPos.Val
            PA_KeSMSwAcsMd30PassStFrwdBkwdPos1_Val: accessed-parameter=KeSMSwAcsMd30PassStFrwdBkwdPos1.Val
            PA_KeSMSwAcsMd30PassStFrwdBkwdPos1Max_Val: accessed-parameter=KeSMSwAcsMd30PassStFrwdBkwdPos1Max.Val
            PA_KeSMSwAcsMd30PassStFrwdBkwdPos1Min_Val: accessed-parameter=KeSMSwAcsMd30PassStFrwdBkwdPos1Min.Val
            PA_KeSMSwAcsMd30PassStFrwdBkwdPosMax_Val: accessed-parameter=KeSMSwAcsMd30PassStFrwdBkwdPosMax.Val
            PA_KeSMSwAcsMd30PassStFrwdBkwdPosMin_Val: accessed-parameter=KeSMSwAcsMd30PassStFrwdBkwdPosMin.Val
            PA_KeSMSwAcsMd31PassStBkReclnUpwdDnwdPos_Val: accessed-parameter=KeSMSwAcsMd31PassStBkReclnUpwdDnwdPos.Val
            PA_KeSMSwAcsMd31PassStBkReclnUpwdDnwdPos1_Val: accessed-parameter=KeSMSwAcsMd31PassStBkReclnUpwdDnwdPos1.Val
            PA_KeSMSwAcsMd31PassStBkReclnUpwdDnwdPos1Max_Val: accessed-parameter=KeSMSwAcsMd31PassStBkReclnUpwdDnwdPos1Max.Val
            PA_KeSMSwAcsMd31PassStBkReclnUpwdDnwdPos1Min_Val: accessed-parameter=KeSMSwAcsMd31PassStBkReclnUpwdDnwdPos1Min.Val
            PA_KeSMSwAcsMd31PassStBkReclnUpwdDnwdPosMax_Val: accessed-parameter=KeSMSwAcsMd31PassStBkReclnUpwdDnwdPosMax.Val
            PA_KeSMSwAcsMd31PassStBkReclnUpwdDnwdPosMin_Val: accessed-parameter=KeSMSwAcsMd31PassStBkReclnUpwdDnwdPosMin.Val
            PA_KeSMSwAcsMd31PassStFldUpwdDnwdPos_Val: accessed-parameter=KeSMSwAcsMd31PassStFldUpwdDnwdPos.Val
            PA_KeSMSwAcsMd31PassStFldUpwdDnwdPosMax_Val: accessed-parameter=KeSMSwAcsMd31PassStFldUpwdDnwdPosMax.Val
            PA_KeSMSwAcsMd31PassStFldUpwdDnwdPosMin_Val: accessed-parameter=KeSMSwAcsMd31PassStFldUpwdDnwdPosMin.Val
            PA_KeSMSwAcsMd31PassStFrwdBkwdPos_Val: accessed-parameter=KeSMSwAcsMd31PassStFrwdBkwdPos.Val
            PA_KeSMSwAcsMd31PassStFrwdBkwdPos1_Val: accessed-parameter=KeSMSwAcsMd31PassStFrwdBkwdPos1.Val
            PA_KeSMSwAcsMd31PassStFrwdBkwdPos1Max_Val: accessed-parameter=KeSMSwAcsMd31PassStFrwdBkwdPos1Max.Val
            PA_KeSMSwAcsMd31PassStFrwdBkwdPos1Min_Val: accessed-parameter=KeSMSwAcsMd31PassStFrwdBkwdPos1Min.Val
            PA_KeSMSwAcsMd31PassStFrwdBkwdPosMax_Val: accessed-parameter=KeSMSwAcsMd31PassStFrwdBkwdPosMax.Val
            PA_KeSMSwAcsMd31PassStFrwdBkwdPosMin_Val: accessed-parameter=KeSMSwAcsMd31PassStFrwdBkwdPosMin.Val
            PA_KeSMSwAcsMd56PassStBkReclnUpwdDnwdPos_Val: accessed-parameter=KeSMSwAcsMd56PassStBkReclnUpwdDnwdPos.Val
            PA_KeSMSwAcsMd56PassStBkReclnUpwdDnwdPosMax_Val: accessed-parameter=KeSMSwAcsMd56PassStBkReclnUpwdDnwdPosMax.Val
            PA_KeSMSwAcsMd56PassStBkReclnUpwdDnwdPosMin_Val: accessed-parameter=KeSMSwAcsMd56PassStBkReclnUpwdDnwdPosMin.Val
            PA_KeSMSwAcsMd56PassStFrwdBkwdPos_Val: accessed-parameter=KeSMSwAcsMd56PassStFrwdBkwdPos.Val
            PA_KeSMSwAcsMd56PassStFrwdBkwdPosMax_Val: accessed-parameter=KeSMSwAcsMd56PassStFrwdBkwdPosMax.Val
            PA_KeSMSwAcsMd56PassStFrwdBkwdPosMin_Val: accessed-parameter=KeSMSwAcsMd56PassStFrwdBkwdPosMin.Val
            PA_KeSMSwAcsMd57PassStBkReclnUpwdDnwdPosPos_Val: accessed-parameter=KeSMSwAcsMd57PassStBkReclnUpwdDnwdPosPos.Val
            PA_KeSMSwAcsMd57PassStBkReclnUpwdDnwdPosPosMax_Val: accessed-parameter=KeSMSwAcsMd57PassStBkReclnUpwdDnwdPosPosMax.Val
            PA_KeSMSwAcsMd57PassStBkReclnUpwdDnwdPosPosMin_Val: accessed-parameter=KeSMSwAcsMd57PassStBkReclnUpwdDnwdPosPosMin.Val
            PA_KeSMSwAcsMd57PassStFoldFwdBkwdPosPos_Val: accessed-parameter=KeSMSwAcsMd57PassStFoldFwdBkwdPosPos.Val
            PA_KeSMSwAcsMd57PassStFoldFwdBkwdPosPos1_Val: accessed-parameter=KeSMSwAcsMd57PassStFoldFwdBkwdPosPos1.Val
            PA_KeSMSwAcsMd57PassStFoldFwdBkwdPosPos1Max_Val: accessed-parameter=KeSMSwAcsMd57PassStFoldFwdBkwdPosPos1Max.Val
            PA_KeSMSwAcsMd57PassStFoldFwdBkwdPosPos1Min_Val: accessed-parameter=KeSMSwAcsMd57PassStFoldFwdBkwdPosPos1Min.Val
            PA_KeSMSwAcsMd57PassStFoldFwdBkwdPosPosMax_Val: accessed-parameter=KeSMSwAcsMd57PassStFoldFwdBkwdPosPosMax.Val
            PA_KeSMSwAcsMd57PassStFoldFwdBkwdPosPosMin_Val: accessed-parameter=KeSMSwAcsMd57PassStFoldFwdBkwdPosPosMin.Val
            PA_KeSMSwAcsMd57PassStFrwdBkwdPosPos1_Val: accessed-parameter=KeSMSwAcsMd57PassStFrwdBkwdPosPos1.Val
            PA_KeSMSwAcsMd57PassStFrwdBkwdPosPos1Max_Val: accessed-parameter=KeSMSwAcsMd57PassStFrwdBkwdPosPos1Max.Val
            PA_KeSMSwAcsMd57PassStFrwdBkwdPosPos1Min_Val: accessed-parameter=KeSMSwAcsMd57PassStFrwdBkwdPosPos1Min.Val
            PA_KeSMSwAcsMd57PassStFrwdBkwdPosPos2_Val: accessed-parameter=KeSMSwAcsMd57PassStFrwdBkwdPosPos2.Val
            PA_KeSMSwAcsMd57PassStFrwdBkwdPosPos2Max_Val: accessed-parameter=KeSMSwAcsMd57PassStFrwdBkwdPosPos2Max.Val
            PA_KeSMSwAcsMd57PassStFrwdBkwdPosPos2Min_Val: accessed-parameter=KeSMSwAcsMd57PassStFrwdBkwdPosPos2Min.Val
            PA_KeSMSwAcsMd58PassStBkReclnUpwdDnwdPosPos1_Val: accessed-parameter=KeSMSwAcsMd58PassStBkReclnUpwdDnwdPosPos1.Val
            PA_KeSMSwAcsMd58PassStBkReclnUpwdDnwdPosPos1Max_Val: accessed-parameter=KeSMSwAcsMd58PassStBkReclnUpwdDnwdPosPos1Max.Val
            PA_KeSMSwAcsMd58PassStBkReclnUpwdDnwdPosPos1Min_Val: accessed-parameter=KeSMSwAcsMd58PassStBkReclnUpwdDnwdPosPos1Min.Val
            PA_KeSMSwAcsMd58PassStFrwdBkwdPosPos1_Val: accessed-parameter=KeSMSwAcsMd58PassStFrwdBkwdPosPos1.Val
            PA_KeSMSwAcsMd58PassStFrwdBkwdPosPos1Max_Val: accessed-parameter=KeSMSwAcsMd58PassStFrwdBkwdPosPos1Max.Val
            PA_KeSMSwAcsMd58PassStFrwdBkwdPosPos1Min_Val: accessed-parameter=KeSMSwAcsMd58PassStFrwdBkwdPosPos1Min.Val
            PA_KeSMSwPassStBkReclnEnTrig557BitMask_Val: accessed-parameter=KeSMSwPassStBkReclnEnTrig557BitMask.Val
            PA_KeSMSwPassStCshnFldEnTrig557BitMask_Val: accessed-parameter=KeSMSwPassStCshnFldEnTrig557BitMask.Val
            PA_KeSMSwPassStFwdBkwdEnTrig557BitMask_Val: accessed-parameter=KeSMSwPassStFwdBkwdEnTrig557BitMask.Val
            PA_KeSMSwRecoveryPassStStFtUpwdDnwdPos_Val: accessed-parameter=KeSMSwRecoveryPassStStFtUpwdDnwdPos.Val
            PA_KeSMSwRecoveryPassStStFtUpwdDnwdPosMax_Val: accessed-parameter=KeSMSwRecoveryPassStStFtUpwdDnwdPosMax.Val
            PA_KeSMSwRecoveryPassStStFtUpwdDnwdPosMin_Val: accessed-parameter=KeSMSwRecoveryPassStStFtUpwdDnwdPosMin.Val
            PA_KeSMSwRevRMDPassStBkReclnUpwdDnwdPos_Val: accessed-parameter=KeSMSwRevRMDPassStBkReclnUpwdDnwdPos.Val
            PA_KeSMSwRevRMDPassStBkReclnUpwdDnwdPosMax_Val: accessed-parameter=KeSMSwRevRMDPassStBkReclnUpwdDnwdPosMax.Val
            PA_KeSMSwRevRMDPassStBkReclnUpwdDnwdPosMin_Val: accessed-parameter=KeSMSwRevRMDPassStBkReclnUpwdDnwdPosMin.Val
            PA_KeSMSwRevRMDPassStFrwdBkwdPos_Val: accessed-parameter=KeSMSwRevRMDPassStFrwdBkwdPos.Val
            PA_KeSMSwRevRMDPassStFrwdBkwdPosMax_Val: accessed-parameter=KeSMSwRevRMDPassStFrwdBkwdPosMax.Val
            PA_KeSMSwRevRMDPassStFrwdBkwdPosMin_Val: accessed-parameter=KeSMSwRevRMDPassStFrwdBkwdPosMin.Val
            PA_KeSMSwVIPMDPassStBkReclnUpwdDnwdPosPos_Val: accessed-parameter=KeSMSwVIPMDPassStBkReclnUpwdDnwdPosPos.Val
            PA_KeSMSwVIPMDPassStBkReclnUpwdDnwdPosPosMax_Val: accessed-parameter=KeSMSwVIPMDPassStBkReclnUpwdDnwdPosPosMax.Val
            PA_KeSMSwVIPMDPassStBkReclnUpwdDnwdPosPosMin_Val: accessed-parameter=KeSMSwVIPMDPassStBkReclnUpwdDnwdPosPosMin.Val
            PA_KeSMSwVIPMDPassStFrwdBkwdPos2_Val: accessed-parameter=KeSMSwVIPMDPassStFrwdBkwdPos2.Val
            PA_KeSMSwVIPMDPassStFrwdBkwdPosMax2_Val: accessed-parameter=KeSMSwVIPMDPassStFrwdBkwdPosMax2.Val
            PA_KeSMSwVIPMDPassStFrwdBkwdPosMin2_Val: accessed-parameter=KeSMSwVIPMDPassStFrwdBkwdPosMin2.Val
            PA_KeSMSwVIPMDPassStFrwdBkwdPosPos_Val: accessed-parameter=KeSMSwVIPMDPassStFrwdBkwdPosPos.Val
            PA_KeSMSwVIPMDPassStFrwdBkwdPosPosMax_Val: accessed-parameter=KeSMSwVIPMDPassStFrwdBkwdPosPosMax.Val
            PA_KeSMSwVIPMDPassStFrwdBkwdPosPosMin_Val: accessed-parameter=KeSMSwVIPMDPassStFrwdBkwdPosPosMin.Val
        PassStFwdBkwdTrgtPosSelc_1_Cal
          data-receive-point-by-arguments:
            11 x access:
              REC_IfVeSMSbSecRwRtStCshnFrntUpwdDnwdMovConfig_Val: accessed-variable=IfVeSMSbSecRwRtStCshnFrntUpwdDnwdMovConfig.Val
              REC_IfVeSMSuPassStBkReclnUpwdDnwdPos_Val: accessed-variable=IfVeSMSuPassStBkReclnUpwdDnwdPos.Val
              REC_IfVeSMSuPassStFldUpwdDnwdPos_Val: accessed-variable=IfVeSMSuPassStFldUpwdDnwdPos.Val
              REC_Md30BkStgDone_Val: accessed-variable=Md30BkStgDone.Val
              REC_Md31BkStgDone_Val: accessed-variable=Md31BkStgDone.Val
              REC_Md61PassStFwdBkwdTrgtPosCalib_TrgtPosArray: accessed-variable=Md61PassStFwdBkwdTrgtPosCalib.TrgtPosArray
              REC_Md62PassStFwdBkwdTrgtPosCalib_TrgtPosArray: accessed-variable=Md62PassStFwdBkwdTrgtPosCalib.TrgtPosArray
              REC_StNumFlg_Is4s: accessed-variable=StNumFlg.Is4s
              REC_StNumFlg_Is6s: accessed-variable=StNumFlg.Is6s
              REC_StNumFlg_Is6s7s: accessed-variable=StNumFlg.Is6s7s
              REC_StNumFlg_Is7s: accessed-variable=StNumFlg.Is7s
          data-send-points:
            6 x access:
              SEND_Md30PassStFwdBkwdTrgtPosCalib1_TrgtPosArray: accessed-variable=Md30PassStFwdBkwdTrgtPosCalib1.TrgtPosArray
              SEND_Md31PassStFwdBkwdTrgtPosCalib1_TrgtPosArray: accessed-variable=Md31PassStFwdBkwdTrgtPosCalib1.TrgtPosArray
              SEND_Md57PassStFwdBkwdTrgtPosCalib1_TrgtPosArray: accessed-variable=Md57PassStFwdBkwdTrgtPosCalib1.TrgtPosArray
              SEND_Md58PassStFwdBkwdTrgtPosCalib1_TrgtPosArray: accessed-variable=Md58PassStFwdBkwdTrgtPosCalib1.TrgtPosArray
              SEND_PassStFwdBkwdStEnTrigBitMask_Val: accessed-variable=PassStFwdBkwdStEnTrigBitMask.Val
              SEND_PassStFwdBkwdTrgtPosCalibArray32_TrgtPosArray32: accessed-variable=PassStFwdBkwdTrgtPosCalibArray32.TrgtPosArray32
          112 x parameter access:
            PA_KeSMSuSecRwStVIPFtrstRefAngle_Val: accessed-parameter=KeSMSuSecRwStVIPFtrstRefAngle.Val
            PA_KeSMSw6sAcsEntryPassStFtUpwdDnwdPos_Val: accessed-parameter=KeSMSw6sAcsEntryPassStFtUpwdDnwdPos.Val
            PA_KeSMSw6sAcsEntryPassStFtUpwdDnwdPosMiax_Val: accessed-parameter=KeSMSw6sAcsEntryPassStFtUpwdDnwdPosMiax.Val
            PA_KeSMSw6sAcsEntryPassStFtUpwdDnwdPosMin_Val: accessed-parameter=KeSMSw6sAcsEntryPassStFtUpwdDnwdPosMin.Val
            PA_KeSMSw6sAcsExtPassStFtUpwdDnwdPos_Val: accessed-parameter=KeSMSw6sAcsExtPassStFtUpwdDnwdPos.Val
            PA_KeSMSw6sAcsExtPassStFtUpwdDnwdPosMax_Val: accessed-parameter=KeSMSw6sAcsExtPassStFtUpwdDnwdPosMax.Val
            PA_KeSMSw6sAcsExtPassStFtUpwdDnwdPosMin_Val: accessed-parameter=KeSMSw6sAcsExtPassStFtUpwdDnwdPosMin.Val
            PA_KeSMSw6sRecoveryPassStStFtUpwdDnwdPos_Val: accessed-parameter=KeSMSw6sRecoveryPassStStFtUpwdDnwdPos.Val
            PA_KeSMSw6sRecoveryPassStStFtUpwdDnwdPosMax_Val: accessed-parameter=KeSMSw6sRecoveryPassStStFtUpwdDnwdPosMax.Val
            PA_KeSMSw6sRecoveryPassStStFtUpwdDnwdPosMin_Val: accessed-parameter=KeSMSw6sRecoveryPassStStFtUpwdDnwdPosMin.Val
            PA_KeSMSw6SVIPMdPassStBkReclnUpwdDnwdPosPos_Val: accessed-parameter=KeSMSw6SVIPMdPassStBkReclnUpwdDnwdPosPos.Val
            PA_KeSMSw6SVIPMdPassStBkReclnUpwdDnwdPosPosMax_Val: accessed-parameter=KeSMSw6SVIPMdPassStBkReclnUpwdDnwdPosPosMax.Val
            PA_KeSMSw6SVIPMdPassStBkReclnUpwdDnwdPosPosMin_Val: accessed-parameter=KeSMSw6SVIPMdPassStBkReclnUpwdDnwdPosPosMin.Val
            PA_KeSMSw6SVIPMdPassStFrwdBkwdPos2_Val: accessed-parameter=KeSMSw6SVIPMdPassStFrwdBkwdPos2.Val
            PA_KeSMSw6SVIPMdPassStFrwdBkwdPosMax2_Val: accessed-parameter=KeSMSw6SVIPMdPassStFrwdBkwdPosMax2.Val
            PA_KeSMSw6SVIPMdPassStFrwdBkwdPosMin2_Val: accessed-parameter=KeSMSw6SVIPMdPassStFrwdBkwdPosMin2.Val
            PA_KeSMSw6SVIPMdPassStFrwdBkwdPosPos_Val: accessed-parameter=KeSMSw6SVIPMdPassStFrwdBkwdPosPos.Val
            PA_KeSMSw6SVIPMdPassStFrwdBkwdPosPosMax_Val: accessed-parameter=KeSMSw6SVIPMdPassStFrwdBkwdPosPosMax.Val
            PA_KeSMSw6SVIPMdPassStFrwdBkwdPosPosMin_Val: accessed-parameter=KeSMSw6SVIPMdPassStFrwdBkwdPosPosMin.Val
            PA_KeSMSwAcsEntryPassStBkReclnUpwdDnwdPos_Val: accessed-parameter=KeSMSwAcsEntryPassStBkReclnUpwdDnwdPos.Val
            PA_KeSMSwAcsEntryPassStBkReclnUpwdDnwdPosMax_Val: accessed-parameter=KeSMSwAcsEntryPassStBkReclnUpwdDnwdPosMax.Val
            PA_KeSMSwAcsEntryPassStBkReclnUpwdDnwdPosMin_Val: accessed-parameter=KeSMSwAcsEntryPassStBkReclnUpwdDnwdPosMin.Val
            PA_KeSMSwAcsEntryPassStFrwdBkwdPos_Val: accessed-parameter=KeSMSwAcsEntryPassStFrwdBkwdPos.Val
            PA_KeSMSwAcsEntryPassStFrwdBkwdPosMax_Val: accessed-parameter=KeSMSwAcsEntryPassStFrwdBkwdPosMax.Val
            PA_KeSMSwAcsEntryPassStFrwdBkwdPosMin_Val: accessed-parameter=KeSMSwAcsEntryPassStFrwdBkwdPosMin.Val
            PA_KeSMSwAcsEntryPassStFtUpwdDnwdPos_Val: accessed-parameter=KeSMSwAcsEntryPassStFtUpwdDnwdPos.Val
            PA_KeSMSwAcsEntryPassStFtUpwdDnwdPosMiax_Val: accessed-parameter=KeSMSwAcsEntryPassStFtUpwdDnwdPosMiax.Val
            PA_KeSMSwAcsEntryPassStFtUpwdDnwdPosMin_Val: accessed-parameter=KeSMSwAcsEntryPassStFtUpwdDnwdPosMin.Val
            PA_KeSMSwAcsExtPassStFtUpwdDnwdPos_Val: accessed-parameter=KeSMSwAcsExtPassStFtUpwdDnwdPos.Val
            PA_KeSMSwAcsExtPassStFtUpwdDnwdPosMax_Val: accessed-parameter=KeSMSwAcsExtPassStFtUpwdDnwdPosMax.Val
            PA_KeSMSwAcsExtPassStFtUpwdDnwdPosMin_Val: accessed-parameter=KeSMSwAcsExtPassStFtUpwdDnwdPosMin.Val
            PA_KeSMSwAcsMd30PassStBkReclnUpwdDnwdPos_Val: accessed-parameter=KeSMSwAcsMd30PassStBkReclnUpwdDnwdPos.Val
            PA_KeSMSwAcsMd30PassStBkReclnUpwdDnwdPos1_Val: accessed-parameter=KeSMSwAcsMd30PassStBkReclnUpwdDnwdPos1.Val
            PA_KeSMSwAcsMd30PassStBkReclnUpwdDnwdPos1Max_Val: accessed-parameter=KeSMSwAcsMd30PassStBkReclnUpwdDnwdPos1Max.Val
            PA_KeSMSwAcsMd30PassStBkReclnUpwdDnwdPos1Min_Val: accessed-parameter=KeSMSwAcsMd30PassStBkReclnUpwdDnwdPos1Min.Val
            PA_KeSMSwAcsMd30PassStBkReclnUpwdDnwdPosMax_Val: accessed-parameter=KeSMSwAcsMd30PassStBkReclnUpwdDnwdPosMax.Val
            PA_KeSMSwAcsMd30PassStBkReclnUpwdDnwdPosMin_Val: accessed-parameter=KeSMSwAcsMd30PassStBkReclnUpwdDnwdPosMin.Val
            PA_KeSMSwAcsMd30PassStFldUpwdDnwdPos_Val: accessed-parameter=KeSMSwAcsMd30PassStFldUpwdDnwdPos.Val
            PA_KeSMSwAcsMd30PassStFldUpwdDnwdPos1_Val: accessed-parameter=KeSMSwAcsMd30PassStFldUpwdDnwdPos1.Val
            PA_KeSMSwAcsMd30PassStFldUpwdDnwdPos1Max_Val: accessed-parameter=KeSMSwAcsMd30PassStFldUpwdDnwdPos1Max.Val
            PA_KeSMSwAcsMd30PassStFldUpwdDnwdPos1Min_Val: accessed-parameter=KeSMSwAcsMd30PassStFldUpwdDnwdPos1Min.Val
            PA_KeSMSwAcsMd30PassStFldUpwdDnwdPosMax_Val: accessed-parameter=KeSMSwAcsMd30PassStFldUpwdDnwdPosMax.Val
            PA_KeSMSwAcsMd30PassStFldUpwdDnwdPosMin_Val: accessed-parameter=KeSMSwAcsMd30PassStFldUpwdDnwdPosMin.Val
            PA_KeSMSwAcsMd30PassStFrwdBkwdPos_Val: accessed-parameter=KeSMSwAcsMd30PassStFrwdBkwdPos.Val
            PA_KeSMSwAcsMd30PassStFrwdBkwdPos1_Val: accessed-parameter=KeSMSwAcsMd30PassStFrwdBkwdPos1.Val
            PA_KeSMSwAcsMd30PassStFrwdBkwdPos1Max_Val: accessed-parameter=KeSMSwAcsMd30PassStFrwdBkwdPos1Max.Val
            PA_KeSMSwAcsMd30PassStFrwdBkwdPos1Min_Val: accessed-parameter=KeSMSwAcsMd30PassStFrwdBkwdPos1Min.Val
            PA_KeSMSwAcsMd30PassStFrwdBkwdPosMax_Val: accessed-parameter=KeSMSwAcsMd30PassStFrwdBkwdPosMax.Val
            PA_KeSMSwAcsMd30PassStFrwdBkwdPosMin_Val: accessed-parameter=KeSMSwAcsMd30PassStFrwdBkwdPosMin.Val
            PA_KeSMSwAcsMd31PassStBkReclnUpwdDnwdPos_Val: accessed-parameter=KeSMSwAcsMd31PassStBkReclnUpwdDnwdPos.Val
            PA_KeSMSwAcsMd31PassStBkReclnUpwdDnwdPos1_Val: accessed-parameter=KeSMSwAcsMd31PassStBkReclnUpwdDnwdPos1.Val
            PA_KeSMSwAcsMd31PassStBkReclnUpwdDnwdPos1Max_Val: accessed-parameter=KeSMSwAcsMd31PassStBkReclnUpwdDnwdPos1Max.Val
            PA_KeSMSwAcsMd31PassStBkReclnUpwdDnwdPos1Min_Val: accessed-parameter=KeSMSwAcsMd31PassStBkReclnUpwdDnwdPos1Min.Val
            PA_KeSMSwAcsMd31PassStBkReclnUpwdDnwdPosMax_Val: accessed-parameter=KeSMSwAcsMd31PassStBkReclnUpwdDnwdPosMax.Val
            PA_KeSMSwAcsMd31PassStBkReclnUpwdDnwdPosMin_Val: accessed-parameter=KeSMSwAcsMd31PassStBkReclnUpwdDnwdPosMin.Val
            PA_KeSMSwAcsMd31PassStFldUpwdDnwdPos_Val: accessed-parameter=KeSMSwAcsMd31PassStFldUpwdDnwdPos.Val
            PA_KeSMSwAcsMd31PassStFldUpwdDnwdPosMax_Val: accessed-parameter=KeSMSwAcsMd31PassStFldUpwdDnwdPosMax.Val
            PA_KeSMSwAcsMd31PassStFldUpwdDnwdPosMin_Val: accessed-parameter=KeSMSwAcsMd31PassStFldUpwdDnwdPosMin.Val
            PA_KeSMSwAcsMd31PassStFrwdBkwdPos_Val: accessed-parameter=KeSMSwAcsMd31PassStFrwdBkwdPos.Val
            PA_KeSMSwAcsMd31PassStFrwdBkwdPos1_Val: accessed-parameter=KeSMSwAcsMd31PassStFrwdBkwdPos1.Val
            PA_KeSMSwAcsMd31PassStFrwdBkwdPos1Max_Val: accessed-parameter=KeSMSwAcsMd31PassStFrwdBkwdPos1Max.Val
            PA_KeSMSwAcsMd31PassStFrwdBkwdPos1Min_Val: accessed-parameter=KeSMSwAcsMd31PassStFrwdBkwdPos1Min.Val
            PA_KeSMSwAcsMd31PassStFrwdBkwdPosMax_Val: accessed-parameter=KeSMSwAcsMd31PassStFrwdBkwdPosMax.Val
            PA_KeSMSwAcsMd31PassStFrwdBkwdPosMin_Val: accessed-parameter=KeSMSwAcsMd31PassStFrwdBkwdPosMin.Val
            PA_KeSMSwAcsMd56PassStBkReclnUpwdDnwdPos_Val: accessed-parameter=KeSMSwAcsMd56PassStBkReclnUpwdDnwdPos.Val
            PA_KeSMSwAcsMd56PassStBkReclnUpwdDnwdPosMax_Val: accessed-parameter=KeSMSwAcsMd56PassStBkReclnUpwdDnwdPosMax.Val
            PA_KeSMSwAcsMd56PassStBkReclnUpwdDnwdPosMin_Val: accessed-parameter=KeSMSwAcsMd56PassStBkReclnUpwdDnwdPosMin.Val
            PA_KeSMSwAcsMd56PassStFrwdBkwdPos_Val: accessed-parameter=KeSMSwAcsMd56PassStFrwdBkwdPos.Val
            PA_KeSMSwAcsMd56PassStFrwdBkwdPosMax_Val: accessed-parameter=KeSMSwAcsMd56PassStFrwdBkwdPosMax.Val
            PA_KeSMSwAcsMd56PassStFrwdBkwdPosMin_Val: accessed-parameter=KeSMSwAcsMd56PassStFrwdBkwdPosMin.Val
            PA_KeSMSwAcsMd57PassStBkReclnUpwdDnwdPosPos_Val: accessed-parameter=KeSMSwAcsMd57PassStBkReclnUpwdDnwdPosPos.Val
            PA_KeSMSwAcsMd57PassStBkReclnUpwdDnwdPosPosMax_Val: accessed-parameter=KeSMSwAcsMd57PassStBkReclnUpwdDnwdPosPosMax.Val
            PA_KeSMSwAcsMd57PassStBkReclnUpwdDnwdPosPosMin_Val: accessed-parameter=KeSMSwAcsMd57PassStBkReclnUpwdDnwdPosPosMin.Val
            PA_KeSMSwAcsMd57PassStFoldFwdBkwdPosPos_Val: accessed-parameter=KeSMSwAcsMd57PassStFoldFwdBkwdPosPos.Val
            PA_KeSMSwAcsMd57PassStFoldFwdBkwdPosPos1_Val: accessed-parameter=KeSMSwAcsMd57PassStFoldFwdBkwdPosPos1.Val
            PA_KeSMSwAcsMd57PassStFoldFwdBkwdPosPos1Max_Val: accessed-parameter=KeSMSwAcsMd57PassStFoldFwdBkwdPosPos1Max.Val
            PA_KeSMSwAcsMd57PassStFoldFwdBkwdPosPos1Min_Val: accessed-parameter=KeSMSwAcsMd57PassStFoldFwdBkwdPosPos1Min.Val
            PA_KeSMSwAcsMd57PassStFoldFwdBkwdPosPosMax_Val: accessed-parameter=KeSMSwAcsMd57PassStFoldFwdBkwdPosPosMax.Val
            PA_KeSMSwAcsMd57PassStFoldFwdBkwdPosPosMin_Val: accessed-parameter=KeSMSwAcsMd57PassStFoldFwdBkwdPosPosMin.Val
            PA_KeSMSwAcsMd57PassStFrwdBkwdPosPos1_Val: accessed-parameter=KeSMSwAcsMd57PassStFrwdBkwdPosPos1.Val
            PA_KeSMSwAcsMd57PassStFrwdBkwdPosPos1Max_Val: accessed-parameter=KeSMSwAcsMd57PassStFrwdBkwdPosPos1Max.Val
            PA_KeSMSwAcsMd57PassStFrwdBkwdPosPos1Min_Val: accessed-parameter=KeSMSwAcsMd57PassStFrwdBkwdPosPos1Min.Val
            PA_KeSMSwAcsMd57PassStFrwdBkwdPosPos2_Val: accessed-parameter=KeSMSwAcsMd57PassStFrwdBkwdPosPos2.Val
            PA_KeSMSwAcsMd57PassStFrwdBkwdPosPos2Max_Val: accessed-parameter=KeSMSwAcsMd57PassStFrwdBkwdPosPos2Max.Val
            PA_KeSMSwAcsMd57PassStFrwdBkwdPosPos2Min_Val: accessed-parameter=KeSMSwAcsMd57PassStFrwdBkwdPosPos2Min.Val
            PA_KeSMSwAcsMd58PassStBkReclnUpwdDnwdPosPos1_Val: accessed-parameter=KeSMSwAcsMd58PassStBkReclnUpwdDnwdPosPos1.Val
            PA_KeSMSwAcsMd58PassStBkReclnUpwdDnwdPosPos1Max_Val: accessed-parameter=KeSMSwAcsMd58PassStBkReclnUpwdDnwdPosPos1Max.Val
            PA_KeSMSwAcsMd58PassStBkReclnUpwdDnwdPosPos1Min_Val: accessed-parameter=KeSMSwAcsMd58PassStBkReclnUpwdDnwdPosPos1Min.Val
            PA_KeSMSwAcsMd58PassStFrwdBkwdPosPos1_Val: accessed-parameter=KeSMSwAcsMd58PassStFrwdBkwdPosPos1.Val
            PA_KeSMSwAcsMd58PassStFrwdBkwdPosPos1Max_Val: accessed-parameter=KeSMSwAcsMd58PassStFrwdBkwdPosPos1Max.Val
            PA_KeSMSwAcsMd58PassStFrwdBkwdPosPos1Min_Val: accessed-parameter=KeSMSwAcsMd58PassStFrwdBkwdPosPos1Min.Val
            PA_KeSMSwPassStBkReclnEnTrig557BitMask_Val: accessed-parameter=KeSMSwPassStBkReclnEnTrig557BitMask.Val
            PA_KeSMSwPassStCshnFldEnTrig557BitMask_Val: accessed-parameter=KeSMSwPassStCshnFldEnTrig557BitMask.Val
            PA_KeSMSwPassStFwdBkwdEnTrig557BitMask_Val: accessed-parameter=KeSMSwPassStFwdBkwdEnTrig557BitMask.Val
            PA_KeSMSwRecoveryPassStStFtUpwdDnwdPos_Val: accessed-parameter=KeSMSwRecoveryPassStStFtUpwdDnwdPos.Val
            PA_KeSMSwRecoveryPassStStFtUpwdDnwdPosMax_Val: accessed-parameter=KeSMSwRecoveryPassStStFtUpwdDnwdPosMax.Val
            PA_KeSMSwRecoveryPassStStFtUpwdDnwdPosMin_Val: accessed-parameter=KeSMSwRecoveryPassStStFtUpwdDnwdPosMin.Val
            PA_KeSMSwRevRMDPassStBkReclnUpwdDnwdPos_Val: accessed-parameter=KeSMSwRevRMDPassStBkReclnUpwdDnwdPos.Val
            PA_KeSMSwRevRMDPassStBkReclnUpwdDnwdPosMax_Val: accessed-parameter=KeSMSwRevRMDPassStBkReclnUpwdDnwdPosMax.Val
            PA_KeSMSwRevRMDPassStBkReclnUpwdDnwdPosMin_Val: accessed-parameter=KeSMSwRevRMDPassStBkReclnUpwdDnwdPosMin.Val
            PA_KeSMSwRevRMDPassStFrwdBkwdPos_Val: accessed-parameter=KeSMSwRevRMDPassStFrwdBkwdPos.Val
            PA_KeSMSwRevRMDPassStFrwdBkwdPosMax_Val: accessed-parameter=KeSMSwRevRMDPassStFrwdBkwdPosMax.Val
            PA_KeSMSwRevRMDPassStFrwdBkwdPosMin_Val: accessed-parameter=KeSMSwRevRMDPassStFrwdBkwdPosMin.Val
            PA_KeSMSwVIPMDPassStBkReclnUpwdDnwdPosPos_Val: accessed-parameter=KeSMSwVIPMDPassStBkReclnUpwdDnwdPosPos.Val
            PA_KeSMSwVIPMDPassStBkReclnUpwdDnwdPosPosMax_Val: accessed-parameter=KeSMSwVIPMDPassStBkReclnUpwdDnwdPosPosMax.Val
            PA_KeSMSwVIPMDPassStBkReclnUpwdDnwdPosPosMin_Val: accessed-parameter=KeSMSwVIPMDPassStBkReclnUpwdDnwdPosPosMin.Val
            PA_KeSMSwVIPMDPassStFrwdBkwdPos2_Val: accessed-parameter=KeSMSwVIPMDPassStFrwdBkwdPos2.Val
            PA_KeSMSwVIPMDPassStFrwdBkwdPosMax2_Val: accessed-parameter=KeSMSwVIPMDPassStFrwdBkwdPosMax2.Val
            PA_KeSMSwVIPMDPassStFrwdBkwdPosMin2_Val: accessed-parameter=KeSMSwVIPMDPassStFrwdBkwdPosMin2.Val
            PA_KeSMSwVIPMDPassStFrwdBkwdPosPos_Val: accessed-parameter=KeSMSwVIPMDPassStFrwdBkwdPosPos.Val
            PA_KeSMSwVIPMDPassStFrwdBkwdPosPosMax_Val: accessed-parameter=KeSMSwVIPMDPassStFrwdBkwdPosPosMax.Val
            PA_KeSMSwVIPMDPassStFrwdBkwdPosPosMin_Val: accessed-parameter=KeSMSwVIPMDPassStFrwdBkwdPosPosMin.Val
          sync call SC_Md58TrgtPos_Get: operation=Md58TrgtPos.Get, timeout=0
          sync call SC_VIPRExit557TrgtPos_Get: operation=VIPRExit557TrgtPos.Get, timeout=0
  swc implementation PassStCalib_Implementation: behavior=PassStCalib_InternalBehavior
    code-descriptors:
      code Default: artifact-descriptors=autosar-engineering-object={short-label=Default, category=SWSRC}
package /PATAC/MSM/ModeAdjust/CalPortInterface
  parameter interface Pos
    parameter data prototype Val: sw-calibration-access=READ-WRITE, type=UInt16
  parameter interface StEnTrigBitMask
    parameter data prototype Val: sw-calibration-access=READ-WRITE, type=UInt32
package /PATAC/MSM/ModeAdjust/DataType
  impl type TrgtPosCalibArray: category=ARRAY, sw-calibration-access=READ-ONLY, type-emitter=RTE  # 0:pos 1:max 2:min
    element Element: array-size=3, array-size-semantics=FIXED-SIZE, implementation-data-type=UInt16, invalid-value=0
  impl type TrgtPosCalibArray32: category=ARRAY, sw-calibration-access=READ-ONLY, type-emitter=RTE  # 0:pos 1:max 2:min
    element Element: array-size=96, array-size-semantics=FIXED-SIZE, implementation-data-type=UInt16, invalid-value=0
package /PATAC/MSM/ModeAdjust/Interfaces
  sender receiver interface IfVeSMSuPassStBkReclnUpwdDnwdPosV: invalidation-policy{data-element=IfVeSMSuPassStBkReclnUpwdDnwdPosV/Val, handle-invalid=DONT-INVALIDATE}
    data Val: type=Boolean
package /PATAC/MSM/ModeAdjust/PortInterface
  6 x client server interface:
    Md58TrgtPos
      operation Get
        12 x arg, all with type=UInt16, direction=OUT, server-argument-impl-policy=USE-ARGUMENT-TYPE:
          SecRwRtStBkReclnTrgtPos
          SecRwRtStZeroTrgtPos
          SecRwRtStLgrstUpwdDnwdTrgtPos
          SecRwRtStLgrstInwdOtwdTrgtPos
          ThdRwLtStBkReclnTrgtPos
          ThdRwLtStFwdBkwdTrgtPos
          ThdRwRtStBkReclnTrgtPos
          ThdRwRtStFwdBkwdTrgtPos
          PassStBkReclnTrgtPos
          PassStFwdBkwdTrgtPos
          SecRwRtStFwdBkwdTrgtPos
          PassStFldTrgtPos
      operation Set
    PassStBkReclnTrgtPosSelc
      operation Cal
    PassStCshnFldTrgtPosSelc
      operation Cal
    PassStFtTrgtPosSelc
      operation Cal
    PassStFwdBkwdTrgtPosSelc
      operation Cal
    VIPRExit557TrgtPos
      operation Get
        11 x arg, all with type=UInt16, direction=OUT, server-argument-impl-policy=USE-ARGUMENT-TYPE:
          SecRwRtStBkReclnTrgtPos
          SecRwRtStZeroTrgtPos
          SecRwRtStLgrstUpwdDnwdTrgtPos
          SecRwRtStLgrstInwdOtwdTrgtPos
          ThdRwLtStBkReclnTrgtPos
          ThdRwLtStFwdBkwdTrgtPos
          ThdRwRtStBkReclnTrgtPos
          ThdRwRtStFwdBkwdTrgtPos
          PassStBkReclnTrgtPos
          PassStFwdBkwdTrgtPos
          SecRwRtStFwdBkwdTrgtPos
      operation Set
  6 x sender receiver interface:
    IfVeSMSuPassStFldUpwdDnwdPos: invalidation-policy{data-element=IfVeSMSuPassStFldUpwdDnwdPos/Val, handle-invalid=DONT-INVALIDATE}
      data Val: type=UInt16
    StEnTrigBitMask: invalidation-policy{data-element=StEnTrigBitMask/Val, handle-invalid=DONT-INVALIDATE}
      data Val: type=UInt32
    StgDone: invalidation-policy{data-element=StgDone/Val, handle-invalid=DONT-INVALIDATE}
      data Val: type=Boolean
    StNumFlg
      4 x data, all with type=Boolean:
        Is4s
        Is6s
        Is6s7s
        Is7s
      invalidation-policys:
        data-element=Is4s, handle-invalid=DONT-INVALIDATE
        data-element=Is6s, handle-invalid=DONT-INVALIDATE
        data-element=Is6s7s, handle-invalid=DONT-INVALIDATE
        data-element=Is7s, handle-invalid=DONT-INVALIDATE
    TrgtPosCalibArray: invalidation-policy{data-element=TrgtPosArray, handle-invalid=DONT-INVALIDATE}
      data TrgtPosArray: type=TrgtPosCalibArray  # 0:Pos 1:Max 2:Min
    TrgtPosCalibArray32: invalidation-policy{data-element=TrgtPosArray32, handle-invalid=DONT-INVALIDATE}
      data TrgtPosArray32: type=TrgtPosCalibArray32  # 0:Pos 1:Max 2:Min
package /PATAC/MSM/PortInterfaces
  parameter interface KeSMSuSecRwStVIPFtrstRefAngle
    parameter data prototype Val: sw-calibration-access=READ-WRITE, type=UInt8
  sender receiver interface IfVeSMSbPassStBkReclnUpwdDnwdMovConfig: invalidation-policy{data-element=IfVeSMSbPassStBkReclnUpwdDnwdMovConfig/Val, handle-invalid=DONT-INVALIDATE}
    data Val: type=Boolean
  sender receiver interface IfVeSMSuPassStBkReclnUpwdDnwdPos: invalidation-policy{data-element=IfVeSMSuPassStBkReclnUpwdDnwdPos/Val, handle-invalid=DONT-INVALIDATE}
    data Val: type=UInt16
  sender receiver interface SeatConfig: invalidation-policy{data-element=SeatConfig/Val, handle-invalid=DONT-INVALIDATE}
    data Val: type=Boolean
